VERSION ""

NS_ :

BS_:

BU_: Central_ECU Radar
VAL_TABLE_ Location_Validity 1 "Valid" 0 "Invalid" ;

BO_ 16 Ego_Vehicle_Movement: 16 Central_ECU
 SG_ Ego_Veh_CRC : 0|16@1+ (1,0) [0|65535] ""  Radar
 SG_ Ego_Veh_AliveCtr : 16|8@1+ (1,0) [0|255] ""  Radar
 SG_ Ego_Veh_YawRate : 56|16@1+ (0.0078125,-180) [-180|180] "deg/s"  Radar
 SG_ Ego_Veh_vx : 24|15@1+ (0.0039063,-25) [-25|100] "m/s"  Radar
 SG_ Ego_Veh_Ax : 40|16@1+ (0.0019531,-59) [-59|59] "m/s^2"  Radar

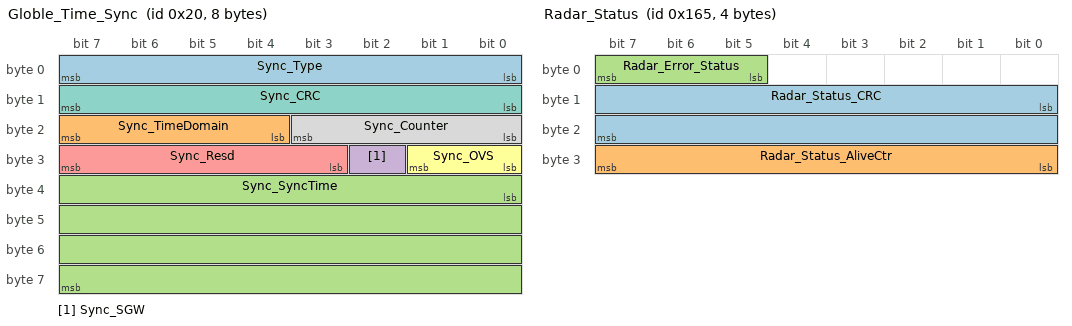
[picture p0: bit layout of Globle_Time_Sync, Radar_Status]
BO_ 32 Globle_Time_Sync: 8 Central_ECU
 SG_ Sync_Type : 0|8@1+ (1,0) [0|255] ""  Radar
 SG_ Sync_TimeDomain : 20|4@1+ (1,0) [0|15] ""  Radar
 SG_ Sync_SyncTime : 32|32@1+ (1,0) [0|4294967295] ""  Radar
 SG_ Sync_SGW : 26|1@1+ (1,0) [0|1] ""  Radar
 SG_ Sync_Resd : 27|5@1+ (1,0) [0|31] ""  Radar
 SG_ Sync_OVS : 24|2@1+ (1,0) [0|3] ""  Radar
 SG_ Sync_CRC : 8|8@1+ (1,0) [0|255] ""  Radar
 SG_ Sync_Counter : 16|4@1+ (1,0) [0|15] ""  Radar

BO_ 1969 Diag_Response: 64 Radar
 SG_ Diag_Response_Dummy : 0|64@1+ (1,0) [0|1.84467440737096E+019] ""  Central_ECU

BO_ 1841 Diag_Req_Physical: 64 Central_ECU
 SG_ Diag_Request_Phys_Dummy : 0|64@1+ (1,0) [0|1.84467440737096E+019] ""  Radar

BO_ 2015 Diag_Req_Functional: 64 Central_ECU
 SG_ Diag_Request_Func_Dummy : 0|64@1+ (1,0) [0|1.84467440737096E+019] ""  Radar

BO_ 357 Radar_Status: 4 Radar
 SG_ Radar_Status_CRC : 8|16@1+ (1,0) [0|65535] "" Vector__XXX
 SG_ Radar_Status_AliveCtr : 24|8@1+ (1,0) [0|255] "" Vector__XXX
 SG_ Radar_Error_Status : 5|3@1+ (1,0) [0|15] ""  Central_ECU

BO_ 256 Loc_List_Header: 12 Radar
 SG_ LocHeader_TimestampStatus : 54|8@1+ (1,0) [0|255] ""  Central_ECU
 SG_ LocHeader_Timestamp : 9|41@1+ (0.1,0) [0|219902325555.1] "ms"  Central_ECU
 SG_ LocHeader_Reserved : 62|10@1+ (1,0) [0|1023] ""  Central_ECU
 SG_ LocHeader_NumLoc : 0|9@1+ (1,0) [0|342] ""  Central_ECU
 SG_ LocHeader_CRC : 72|16@1+ (1,0) [0|65535] ""  Central_ECU
 SG_ LocHeader_Blockcnt : 50|4@1+ (1,0) [0|15] ""  Central_ECU
 SG_ LocHeader_AliveCtr : 88|8@1+ (1,0) [0|255] ""  Central_ECU

BO_ 356 Location_Data_64: 64 Radar
 SG_ Loc_ElevAngleQly_64_004 : 416|8@1+ (1,0) [0|255] ""  Central_ECU
 SG_ Loc_ElevAngleQly_64_003 : 392|8@1+ (1,0) [0|255] ""  Central_ECU
 SG_ Loc_ElevAngleQly_64_002 : 368|8@1+ (1,0) [0|255] ""  Central_ECU
 SG_ Loc_ElevAngleQly_64_001 : 344|8@1+ (1,0) [0|255] ""  Central_ECU
 SG_ Loc_AziAngleQly_64_004 : 408|8@1+ (1,0) [0|255] ""  Central_ECU
 SG_ Loc_AziAngleQly_64_003 : 384|8@1+ (1,0) [0|255] ""  Central_ECU
 SG_ Loc_AziAngleQly_64_002 : 360|8@1+ (1,0) [0|255] ""  Central_ECU
 SG_ Loc_AziAngleQly_64_001 : 336|8@1+ (1,0) [0|255] ""  Central_ECU
 SG_ Loc_RadialDistVeloQly_64_004 : 400|8@1+ (1,0) [0|255] ""  Central_ECU
 SG_ Loc_RadialDistVeloQly_64_003 : 376|8@1+ (1,0) [0|255] ""  Central_ECU
 SG_ Loc_RadialDistVeloQly_64_002 : 352|8@1+ (1,0) [0|255] ""  Central_ECU
 SG_ Loc_RadialDistVeloQly_64_001 : 328|8@1+ (1,0) [0|255] ""  Central_ECU
 SG_ Loc_Validity_64_004 : 327|1@1+ (1,0) [0|1] ""  Central_ECU
 SG_ Loc_Validity_64_003 : 326|1@1+ (1,0) [0|1] ""  Central_ECU
 SG_ Loc_Validity_64_002 : 325|1@1+ (1,0) [0|1] ""  Central_ECU
 SG_ Loc_Validity_64_001 : 324|1@1+ (1,0) [0|1] ""  Central_ECU
 SG_ Loc_64_Blockcnt : 320|4@1+ (1,0) [0|15] ""  Central_ECU
 SG_ Loc_64_CRC : 296|16@1+ (1,0) [0|65535] ""  Central_ECU
 SG_ Loc_64_AliveCtr : 312|8@1+ (1,0) [0|255] ""  Central_ECU
 SG_ Loc_SNR_64_004 : 237|11@1+ (0.0625,0) [0|40] "dB"  Central_ECU
 SG_ Loc_SNR_64_003 : 163|11@1+ (0.0625,0) [0|40] "dB"  Central_ECU
 SG_ Loc_SNR_64_002 : 89|11@1+ (0.0625,0) [0|40] "dB"  Central_ECU
 SG_ Loc_RCS_64_004 : 286|10@1+ (0.125,-50) [-50|70] "dBm^2"  Central_ECU
 SG_ Loc_RCS_64_003 : 212|10@1+ (0.125,-50) [-50|70] "dBm^2"  Central_ECU
 SG_ Loc_RCS_64_002 : 138|10@1+ (0.125,-50) [-50|70] "dBm^2"  Central_ECU
 SG_ Loc_RadialVelo_64_004 : 248|15@1+ (0.0078125,-128) [-128|127] "m/s"  Central_ECU
 SG_ Loc_RadialVelo_64_003 : 174|15@1+ (0.0078125,-128) [-128|127] "m/s"  Central_ECU
 SG_ Loc_RadialVelo_64_002 : 100|15@1+ (0.0078125,-128) [-128|127] "m/s"  Central_ECU
 SG_ Loc_RadialDist_64_004 : 222|15@1+ (0.0078125,0) [0|250] "m"  Central_ECU
 SG_ Loc_RadialDist_64_003 : 148|15@1+ (0.0078125,0) [0|250] "m"  Central_ECU
 SG_ Loc_RadialDist_64_002 : 74|15@1+ (0.0078125,0) [0|250] "m"  Central_ECU
 SG_ Loc_ElevAngle_64_004 : 275|11@1+ (0.001,-0.785) [-0.785|0.785] "rad"  Central_ECU
 SG_ Loc_ElevAngle_64_003 : 201|11@1+ (0.001,-0.785) [-0.785|0.785] "rad"  Central_ECU
 SG_ Loc_ElevAngle_64_002 : 127|11@1+ (0.001,-0.785) [-0.785|0.785] "rad"  Central_ECU
 SG_ Loc_AziAngle_64_004 : 263|12@1+ (0.001,-1.57) [-1.57|1.57] "rad"  Central_ECU
 SG_ Loc_AziAngle_64_003 : 189|12@1+ (0.001,-1.57) [-1.57|1.57] "rad"  Central_ECU
 SG_ Loc_AziAngle_64_002 : 115|12@1+ (0.001,-1.57) [-1.57|1.57] "rad"  Central_ECU
 SG_ Loc_RCS_64_001 : 64|10@1+ (0.125,-50) [-50|70] "dBm^2"  Central_ECU
 SG_ Loc_ElevAngle_64_001 : 53|11@1+ (0.001,-0.785) [-0.785|0.785] "rad"  Central_ECU
 SG_ Loc_AziAngle_64_001 : 41|12@1+ (0.001,-1.57) [-1.57|1.57] "rad"  Central_ECU
 SG_ Loc_RadialVelo_64_001 : 26|15@1+ (0.0078125,-128) [-128|127] "m/s"  Central_ECU
 SG_ Loc_SNR_64_001 : 15|11@1+ (0.0625,0) [0|40] "dB"  Central_ECU
 SG_ Loc_RadialDist_64_001 : 0|15@1+ (0.0078125,0) [0|250] "m"  Central_ECU

BO_ 355 Location_Data_63: 64 Radar
 SG_ Loc_ElevAngleQly_63_004 : 416|8@1+ (1,0) [0|255] ""  Central_ECU
 SG_ Loc_ElevAngleQly_63_003 : 392|8@1+ (1,0) [0|255] ""  Central_ECU
 SG_ Loc_ElevAngleQly_63_002 : 368|8@1+ (1,0) [0|255] ""  Central_ECU
 SG_ Loc_ElevAngleQly_63_001 : 344|8@1+ (1,0) [0|255] ""  Central_ECU
 SG_ Loc_AziAngleQly_63_004 : 408|8@1+ (1,0) [0|255] ""  Central_ECU
 SG_ Loc_AziAngleQly_63_003 : 384|8@1+ (1,0) [0|255] ""  Central_ECU
 SG_ Loc_AziAngleQly_63_002 : 360|8@1+ (1,0) [0|255] ""  Central_ECU
 SG_ Loc_AziAngleQly_63_001 : 336|8@1+ (1,0) [0|255] ""  Central_ECU
 SG_ Loc_RadialDistVeloQly_63_004 : 400|8@1+ (1,0) [0|255] ""  Central_ECU
 SG_ Loc_RadialDistVeloQly_63_003 : 376|8@1+ (1,0) [0|255] ""  Central_ECU
 SG_ Loc_RadialDistVeloQly_63_002 : 352|8@1+ (1,0) [0|255] ""  Central_ECU
 SG_ Loc_RadialDistVeloQly_63_001 : 328|8@1+ (1,0) [0|255] ""  Central_ECU
 SG_ Loc_Validity_63_004 : 327|1@1+ (1,0) [0|1] ""  Central_ECU
 SG_ Loc_Validity_63_003 : 326|1@1+ (1,0) [0|1] ""  Central_ECU
 SG_ Loc_Validity_63_002 : 325|1@1+ (1,0) [0|1] ""  Central_ECU
 SG_ Loc_Validity_63_001 : 324|1@1+ (1,0) [0|1] ""  Central_ECU
 SG_ Loc_63_Blockcnt : 320|4@1+ (1,0) [0|15] ""  Central_ECU
 SG_ Loc_63_CRC : 296|16@1+ (1,0) [0|65535] ""  Central_ECU
 SG_ Loc_63_AliveCtr : 312|8@1+ (1,0) [0|255] ""  Central_ECU
 SG_ Loc_SNR_63_004 : 237|11@1+ (0.0625,0) [0|40] "dB"  Central_ECU
 SG_ Loc_SNR_63_003 : 163|11@1+ (0.0625,0) [0|40] "dB"  Central_ECU
 SG_ Loc_SNR_63_002 : 89|11@1+ (0.0625,0) [0|40] "dB"  Central_ECU
 SG_ Loc_RCS_63_004 : 286|10@1+ (0.125,-50) [-50|70] "dBm^2"  Central_ECU
 SG_ Loc_RCS_63_003 : 212|10@1+ (0.125,-50) [-50|70] "dBm^2"  Central_ECU
 SG_ Loc_RCS_63_002 : 138|10@1+ (0.125,-50) [-50|70] "dBm^2"  Central_ECU
 SG_ Loc_RadialVelo_63_004 : 248|15@1+ (0.0078125,-128) [-128|127] "m/s"  Central_ECU
 SG_ Loc_RadialVelo_63_003 : 174|15@1+ (0.0078125,-128) [-128|127] "m/s"  Central_ECU
 SG_ Loc_RadialVelo_63_002 : 100|15@1+ (0.0078125,-128) [-128|127] "m/s"  Central_ECU
 SG_ Loc_RadialDist_63_004 : 222|15@1+ (0.0078125,0) [0|250] "m"  Central_ECU
 SG_ Loc_RadialDist_63_003 : 148|15@1+ (0.0078125,0) [0|250] "m"  Central_ECU
 SG_ Loc_RadialDist_63_002 : 74|15@1+ (0.0078125,0) [0|250] "m"  Central_ECU
 SG_ Loc_ElevAngle_63_004 : 275|11@1+ (0.001,-0.785) [-0.785|0.785] "rad"  Central_ECU
 SG_ Loc_ElevAngle_63_003 : 201|11@1+ (0.001,-0.785) [-0.785|0.785] "rad"  Central_ECU
 SG_ Loc_ElevAngle_63_002 : 127|11@1+ (0.001,-0.785) [-0.785|0.785] "rad"  Central_ECU
 SG_ Loc_AziAngle_63_004 : 263|12@1+ (0.001,-1.57) [-1.57|1.57] "rad"  Central_ECU
 SG_ Loc_AziAngle_63_003 : 189|12@1+ (0.001,-1.57) [-1.57|1.57] "rad"  Central_ECU
 SG_ Loc_AziAngle_63_002 : 115|12@1+ (0.001,-1.57) [-1.57|1.57] "rad"  Central_ECU
 SG_ Loc_RCS_63_001 : 64|10@1+ (0.125,-50) [-50|70] "dBm^2"  Central_ECU
 SG_ Loc_ElevAngle_63_001 : 53|11@1+ (0.001,-0.785) [-0.785|0.785] "rad"  Central_ECU
 SG_ Loc_AziAngle_63_001 : 41|12@1+ (0.001,-1.57) [-1.57|1.57] "rad"  Central_ECU
 SG_ Loc_RadialVelo_63_001 : 26|15@1+ (0.0078125,-128) [-128|127] "m/s"  Central_ECU
 SG_ Loc_SNR_63_001 : 15|11@1+ (0.0625,0) [0|40] "dB"  Central_ECU
 SG_ Loc_RadialDist_63_001 : 0|15@1+ (0.0078125,0) [0|250] "m"  Central_ECU

BO_ 354 Location_Data_62: 64 Radar
 SG_ Loc_ElevAngleQly_62_004 : 416|8@1+ (1,0) [0|255] ""  Central_ECU
 SG_ Loc_ElevAngleQly_62_003 : 392|8@1+ (1,0) [0|255] ""  Central_ECU
 SG_ Loc_ElevAngleQly_62_002 : 368|8@1+ (1,0) [0|255] ""  Central_ECU
 SG_ Loc_ElevAngleQly_62_001 : 344|8@1+ (1,0) [0|255] ""  Central_ECU
 SG_ Loc_AziAngleQly_62_004 : 408|8@1+ (1,0) [0|255] ""  Central_ECU
 SG_ Loc_AziAngleQly_62_003 : 384|8@1+ (1,0) [0|255] ""  Central_ECU
 SG_ Loc_AziAngleQly_62_002 : 360|8@1+ (1,0) [0|255] ""  Central_ECU
 SG_ Loc_AziAngleQly_62_001 : 336|8@1+ (1,0) [0|255] ""  Central_ECU
 SG_ Loc_RadialDistVeloQly_62_004 : 400|8@1+ (1,0) [0|255] ""  Central_ECU
 SG_ Loc_RadialDistVeloQly_62_003 : 376|8@1+ (1,0) [0|255] ""  Central_ECU
 SG_ Loc_RadialDistVeloQly_62_002 : 352|8@1+ (1,0) [0|255] ""  Central_ECU
 SG_ Loc_RadialDistVeloQly_62_001 : 328|8@1+ (1,0) [0|255] ""  Central_ECU
 SG_ Loc_Validity_62_004 : 327|1@1+ (1,0) [0|1] ""  Central_ECU
 SG_ Loc_Validity_62_003 : 326|1@1+ (1,0) [0|1] ""  Central_ECU
 SG_ Loc_Validity_62_002 : 325|1@1+ (1,0) [0|1] ""  Central_ECU
 SG_ Loc_Validity_62_001 : 324|1@1+ (1,0) [0|1] ""  Central_ECU
 SG_ Loc_62_Blockcnt : 320|4@1+ (1,0) [0|15] ""  Central_ECU
 SG_ Loc_62_CRC : 296|16@1+ (1,0) [0|65535] ""  Central_ECU
 SG_ Loc_62_AliveCtr : 312|8@1+ (1,0) [0|255] ""  Central_ECU
 SG_ Loc_SNR_62_004 : 237|11@1+ (0.0625,0) [0|40] "dB"  Central_ECU
 SG_ Loc_SNR_62_003 : 163|11@1+ (0.0625,0) [0|40] "dB"  Central_ECU
 SG_ Loc_SNR_62_002 : 89|11@1+ (0.0625,0) [0|40] "dB"  Central_ECU
 SG_ Loc_RCS_62_004 : 286|10@1+ (0.125,-50) [-50|70] "dBm^2"  Central_ECU
 SG_ Loc_RCS_62_003 : 212|10@1+ (0.125,-50) [-50|70] "dBm^2"  Central_ECU
 SG_ Loc_RCS_62_002 : 138|10@1+ (0.125,-50) [-50|70] "dBm^2"  Central_ECU
 SG_ Loc_RadialVelo_62_004 : 248|15@1+ (0.0078125,-128) [-128|127] "m/s"  Central_ECU
 SG_ Loc_RadialVelo_62_003 : 174|15@1+ (0.0078125,-128) [-128|127] "m/s"  Central_ECU
 SG_ Loc_RadialVelo_62_002 : 100|15@1+ (0.0078125,-128) [-128|127] "m/s"  Central_ECU
 SG_ Loc_RadialDist_62_004 : 222|15@1+ (0.0078125,0) [0|250] "m"  Central_ECU
 SG_ Loc_RadialDist_62_003 : 148|15@1+ (0.0078125,0) [0|250] "m"  Central_ECU
 SG_ Loc_RadialDist_62_002 : 74|15@1+ (0.0078125,0) [0|250] "m"  Central_ECU
 SG_ Loc_ElevAngle_62_004 : 275|11@1+ (0.001,-0.785) [-0.785|0.785] "rad"  Central_ECU
 SG_ Loc_ElevAngle_62_003 : 201|11@1+ (0.001,-0.785) [-0.785|0.785] "rad"  Central_ECU
 SG_ Loc_ElevAngle_62_002 : 127|11@1+ (0.001,-0.785) [-0.785|0.785] "rad"  Central_ECU
 SG_ Loc_AziAngle_62_004 : 263|12@1+ (0.001,-1.57) [-1.57|1.57] "rad"  Central_ECU
 SG_ Loc_AziAngle_62_003 : 189|12@1+ (0.001,-1.57) [-1.57|1.57] "rad"  Central_ECU
 SG_ Loc_AziAngle_62_002 : 115|12@1+ (0.001,-1.57) [-1.57|1.57] "rad"  Central_ECU
 SG_ Loc_RCS_62_001 : 64|10@1+ (0.125,-50) [-50|70] "dBm^2"  Central_ECU
 SG_ Loc_ElevAngle_62_001 : 53|11@1+ (0.001,-0.785) [-0.785|0.785] "rad"  Central_ECU
 SG_ Loc_AziAngle_62_001 : 41|12@1+ (0.001,-1.57) [-1.57|1.57] "rad"  Central_ECU
 SG_ Loc_RadialVelo_62_001 : 26|15@1+ (0.0078125,-128) [-128|127] "m/s"  Central_ECU
 SG_ Loc_SNR_62_001 : 15|11@1+ (0.0625,0) [0|40] "dB"  Central_ECU
 SG_ Loc_RadialDist_62_001 : 0|15@1+ (0.0078125,0) [0|250] "m"  Central_ECU

BO_ 353 Location_Data_61: 64 Radar
 SG_ Loc_ElevAngleQly_61_004 : 416|8@1+ (1,0) [0|255] ""  Central_ECU
 SG_ Loc_ElevAngleQly_61_003 : 392|8@1+ (1,0) [0|255] ""  Central_ECU
 SG_ Loc_ElevAngleQly_61_002 : 368|8@1+ (1,0) [0|255] ""  Central_ECU
 SG_ Loc_ElevAngleQly_61_001 : 344|8@1+ (1,0) [0|255] ""  Central_ECU
 SG_ Loc_AziAngleQly_61_004 : 408|8@1+ (1,0) [0|255] ""  Central_ECU
 SG_ Loc_AziAngleQly_61_003 : 384|8@1+ (1,0) [0|255] ""  Central_ECU
 SG_ Loc_AziAngleQly_61_002 : 360|8@1+ (1,0) [0|255] ""  Central_ECU
 SG_ Loc_AziAngleQly_61_001 : 336|8@1+ (1,0) [0|255] ""  Central_ECU
 SG_ Loc_RadialDistVeloQly_61_004 : 400|8@1+ (1,0) [0|255] ""  Central_ECU
 SG_ Loc_RadialDistVeloQly_61_003 : 376|8@1+ (1,0) [0|255] ""  Central_ECU
 SG_ Loc_RadialDistVeloQly_61_002 : 352|8@1+ (1,0) [0|255] ""  Central_ECU
 SG_ Loc_RadialDistVeloQly_61_001 : 328|8@1+ (1,0) [0|255] ""  Central_ECU
 SG_ Loc_Validity_61_004 : 327|1@1+ (1,0) [0|1] ""  Central_ECU
 SG_ Loc_Validity_61_003 : 326|1@1+ (1,0) [0|1] ""  Central_ECU
 SG_ Loc_Validity_61_002 : 325|1@1+ (1,0) [0|1] ""  Central_ECU
 SG_ Loc_Validity_61_001 : 324|1@1+ (1,0) [0|1] ""  Central_ECU
 SG_ Loc_61_Blockcnt : 320|4@1+ (1,0) [0|15] ""  Central_ECU
 SG_ Loc_61_CRC : 296|16@1+ (1,0) [0|65535] ""  Central_ECU
 SG_ Loc_61_AliveCtr : 312|8@1+ (1,0) [0|255] ""  Central_ECU
 SG_ Loc_SNR_61_004 : 237|11@1+ (0.0625,0) [0|40] "dB"  Central_ECU
 SG_ Loc_SNR_61_003 : 163|11@1+ (0.0625,0) [0|40] "dB"  Central_ECU
 SG_ Loc_SNR_61_002 : 89|11@1+ (0.0625,0) [0|40] "dB"  Central_ECU
 SG_ Loc_RCS_61_004 : 286|10@1+ (0.125,-50) [-50|70] "dBm^2"  Central_ECU
 SG_ Loc_RCS_61_003 : 212|10@1+ (0.125,-50) [-50|70] "dBm^2"  Central_ECU
 SG_ Loc_RCS_61_002 : 138|10@1+ (0.125,-50) [-50|70] "dBm^2"  Central_ECU
 SG_ Loc_RadialVelo_61_004 : 248|15@1+ (0.0078125,-128) [-128|127] "m/s"  Central_ECU
 SG_ Loc_RadialVelo_61_003 : 174|15@1+ (0.0078125,-128) [-128|127] "m/s"  Central_ECU
 SG_ Loc_RadialVelo_61_002 : 100|15@1+ (0.0078125,-128) [-128|127] "m/s"  Central_ECU
 SG_ Loc_RadialDist_61_004 : 222|15@1+ (0.0078125,0) [0|250] "m"  Central_ECU
 SG_ Loc_RadialDist_61_003 : 148|15@1+ (0.0078125,0) [0|250] "m"  Central_ECU
 SG_ Loc_RadialDist_61_002 : 74|15@1+ (0.0078125,0) [0|250] "m"  Central_ECU
 SG_ Loc_ElevAngle_61_004 : 275|11@1+ (0.001,-0.785) [-0.785|0.785] "rad"  Central_ECU
 SG_ Loc_ElevAngle_61_003 : 201|11@1+ (0.001,-0.785) [-0.785|0.785] "rad"  Central_ECU
 SG_ Loc_ElevAngle_61_002 : 127|11@1+ (0.001,-0.785) [-0.785|0.785] "rad"  Central_ECU
 SG_ Loc_AziAngle_61_004 : 263|12@1+ (0.001,-1.57) [-1.57|1.57] "rad"  Central_ECU
 SG_ Loc_AziAngle_61_003 : 189|12@1+ (0.001,-1.57) [-1.57|1.57] "rad"  Central_ECU
 SG_ Loc_AziAngle_61_002 : 115|12@1+ (0.001,-1.57) [-1.57|1.57] "rad"  Central_ECU
 SG_ Loc_RCS_61_001 : 64|10@1+ (0.125,-50) [-50|70] "dBm^2"  Central_ECU
 SG_ Loc_ElevAngle_61_001 : 53|11@1+ (0.001,-0.785) [-0.785|0.785] "rad"  Central_ECU
 SG_ Loc_AziAngle_61_001 : 41|12@1+ (0.001,-1.57) [-1.57|1.57] "rad"  Central_ECU
 SG_ Loc_RadialVelo_61_001 : 26|15@1+ (0.0078125,-128) [-128|127] "m/s"  Central_ECU
 SG_ Loc_SNR_61_001 : 15|11@1+ (0.0625,0) [0|40] "dB"  Central_ECU
 SG_ Loc_RadialDist_61_001 : 0|15@1+ (0.0078125,0) [0|250] "m"  Central_ECU

BO_ 352 Location_Data_60: 64 Radar
 SG_ Loc_ElevAngleQly_60_004 : 416|8@1+ (1,0) [0|255] ""  Central_ECU
 SG_ Loc_ElevAngleQly_60_003 : 392|8@1+ (1,0) [0|255] ""  Central_ECU
 SG_ Loc_ElevAngleQly_60_002 : 368|8@1+ (1,0) [0|255] ""  Central_ECU
 SG_ Loc_ElevAngleQly_60_001 : 344|8@1+ (1,0) [0|255] ""  Central_ECU
 SG_ Loc_AziAngleQly_60_004 : 408|8@1+ (1,0) [0|255] ""  Central_ECU
 SG_ Loc_AziAngleQly_60_003 : 384|8@1+ (1,0) [0|255] ""  Central_ECU
 SG_ Loc_AziAngleQly_60_002 : 360|8@1+ (1,0) [0|255] ""  Central_ECU
 SG_ Loc_AziAngleQly_60_001 : 336|8@1+ (1,0) [0|255] ""  Central_ECU
 SG_ Loc_RadialDistVeloQly_60_004 : 400|8@1+ (1,0) [0|255] ""  Central_ECU
 SG_ Loc_RadialDistVeloQly_60_003 : 376|8@1+ (1,0) [0|255] ""  Central_ECU
 SG_ Loc_RadialDistVeloQly_60_002 : 352|8@1+ (1,0) [0|255] ""  Central_ECU
 SG_ Loc_RadialDistVeloQly_60_001 : 328|8@1+ (1,0) [0|255] ""  Central_ECU
 SG_ Loc_Validity_60_004 : 327|1@1+ (1,0) [0|1] ""  Central_ECU
 SG_ Loc_Validity_60_003 : 326|1@1+ (1,0) [0|1] ""  Central_ECU
 SG_ Loc_Validity_60_002 : 325|1@1+ (1,0) [0|1] ""  Central_ECU
 SG_ Loc_Validity_60_001 : 324|1@1+ (1,0) [0|1] ""  Central_ECU
 SG_ Loc_60_Blockcnt : 320|4@1+ (1,0) [0|15] ""  Central_ECU
 SG_ Loc_60_CRC : 296|16@1+ (1,0) [0|65535] ""  Central_ECU
 SG_ Loc_60_AliveCtr : 312|8@1+ (1,0) [0|255] ""  Central_ECU
 SG_ Loc_SNR_60_004 : 237|11@1+ (0.0625,0) [0|40] "dB"  Central_ECU
 SG_ Loc_SNR_60_003 : 163|11@1+ (0.0625,0) [0|40] "dB"  Central_ECU
 SG_ Loc_SNR_60_002 : 89|11@1+ (0.0625,0) [0|40] "dB"  Central_ECU
 SG_ Loc_RCS_60_004 : 286|10@1+ (0.125,-50) [-50|70] "dBm^2"  Central_ECU
 SG_ Loc_RCS_60_003 : 212|10@1+ (0.125,-50) [-50|70] "dBm^2"  Central_ECU
 SG_ Loc_RCS_60_002 : 138|10@1+ (0.125,-50) [-50|70] "dBm^2"  Central_ECU
 SG_ Loc_RadialVelo_60_004 : 248|15@1+ (0.0078125,-128) [-128|127] "m/s"  Central_ECU
 SG_ Loc_RadialVelo_60_003 : 174|15@1+ (0.0078125,-128) [-128|127] "m/s"  Central_ECU
 SG_ Loc_RadialVelo_60_002 : 100|15@1+ (0.0078125,-128) [-128|127] "m/s"  Central_ECU
 SG_ Loc_RadialDist_60_004 : 222|15@1+ (0.0078125,0) [0|250] "m"  Central_ECU
 SG_ Loc_RadialDist_60_003 : 148|15@1+ (0.0078125,0) [0|250] "m"  Central_ECU
 SG_ Loc_RadialDist_60_002 : 74|15@1+ (0.0078125,0) [0|250] "m"  Central_ECU
 SG_ Loc_ElevAngle_60_004 : 275|11@1+ (0.001,-0.785) [-0.785|0.785] "rad"  Central_ECU
 SG_ Loc_ElevAngle_60_003 : 201|11@1+ (0.001,-0.785) [-0.785|0.785] "rad"  Central_ECU
 SG_ Loc_ElevAngle_60_002 : 127|11@1+ (0.001,-0.785) [-0.785|0.785] "rad"  Central_ECU
 SG_ Loc_AziAngle_60_004 : 263|12@1+ (0.001,-1.57) [-1.57|1.57] "rad"  Central_ECU
 SG_ Loc_AziAngle_60_003 : 189|12@1+ (0.001,-1.57) [-1.57|1.57] "rad"  Central_ECU
 SG_ Loc_AziAngle_60_002 : 115|12@1+ (0.001,-1.57) [-1.57|1.57] "rad"  Central_ECU
 SG_ Loc_RCS_60_001 : 64|10@1+ (0.125,-50) [-50|70] "dBm^2"  Central_ECU
 SG_ Loc_ElevAngle_60_001 : 53|11@1+ (0.001,-0.785) [-0.785|0.785] "rad"  Central_ECU
 SG_ Loc_AziAngle_60_001 : 41|12@1+ (0.001,-1.57) [-1.57|1.57] "rad"  Central_ECU
 SG_ Loc_RadialVelo_60_001 : 26|15@1+ (0.0078125,-128) [-128|127] "m/s"  Central_ECU
 SG_ Loc_SNR_60_001 : 15|11@1+ (0.0625,0) [0|40] "dB"  Central_ECU
 SG_ Loc_RadialDist_60_001 : 0|15@1+ (0.0078125,0) [0|250] "m"  Central_ECU

BO_ 345 Location_Data_59: 64 Radar
 SG_ Loc_ElevAngleQly_59_004 : 416|8@1+ (1,0) [0|255] ""  Central_ECU
 SG_ Loc_ElevAngleQly_59_003 : 392|8@1+ (1,0) [0|255] ""  Central_ECU
 SG_ Loc_ElevAngleQly_59_002 : 368|8@1+ (1,0) [0|255] ""  Central_ECU
 SG_ Loc_ElevAngleQly_59_001 : 344|8@1+ (1,0) [0|255] ""  Central_ECU
 SG_ Loc_AziAngleQly_59_004 : 408|8@1+ (1,0) [0|255] ""  Central_ECU
 SG_ Loc_AziAngleQly_59_003 : 384|8@1+ (1,0) [0|255] ""  Central_ECU
 SG_ Loc_AziAngleQly_59_002 : 360|8@1+ (1,0) [0|255] ""  Central_ECU
 SG_ Loc_AziAngleQly_59_001 : 336|8@1+ (1,0) [0|255] ""  Central_ECU
 SG_ Loc_RadialDistVeloQly_59_004 : 400|8@1+ (1,0) [0|255] ""  Central_ECU
 SG_ Loc_RadialDistVeloQly_59_003 : 376|8@1+ (1,0) [0|255] ""  Central_ECU
 SG_ Loc_RadialDistVeloQly_59_002 : 352|8@1+ (1,0) [0|255] ""  Central_ECU
 SG_ Loc_RadialDistVeloQly_59_001 : 328|8@1+ (1,0) [0|255] ""  Central_ECU
 SG_ Loc_Validity_59_004 : 327|1@1+ (1,0) [0|1] ""  Central_ECU
 SG_ Loc_Validity_59_003 : 326|1@1+ (1,0) [0|1] ""  Central_ECU
 SG_ Loc_Validity_59_002 : 325|1@1+ (1,0) [0|1] ""  Central_ECU
 SG_ Loc_Validity_59_001 : 324|1@1+ (1,0) [0|1] ""  Central_ECU
 SG_ Loc_59_Blockcnt : 320|4@1+ (1,0) [0|15] ""  Central_ECU
 SG_ Loc_59_CRC : 296|16@1+ (1,0) [0|65535] ""  Central_ECU
 SG_ Loc_59_AliveCtr : 312|8@1+ (1,0) [0|255] ""  Central_ECU
 SG_ Loc_SNR_59_004 : 237|11@1+ (0.0625,0) [0|40] "dB"  Central_ECU
 SG_ Loc_SNR_59_003 : 163|11@1+ (0.0625,0) [0|40] "dB"  Central_ECU
 SG_ Loc_SNR_59_002 : 89|11@1+ (0.0625,0) [0|40] "dB"  Central_ECU
 SG_ Loc_RCS_59_004 : 286|10@1+ (0.125,-50) [-50|70] "dBm^2"  Central_ECU
 SG_ Loc_RCS_59_003 : 212|10@1+ (0.125,-50) [-50|70] "dBm^2"  Central_ECU
 SG_ Loc_RCS_59_002 : 138|10@1+ (0.125,-50) [-50|70] "dBm^2"  Central_ECU
 SG_ Loc_RadialVelo_59_004 : 248|15@1+ (0.0078125,-128) [-128|127] "m/s"  Central_ECU
 SG_ Loc_RadialVelo_59_003 : 174|15@1+ (0.0078125,-128) [-128|127] "m/s"  Central_ECU
 SG_ Loc_RadialVelo_59_002 : 100|15@1+ (0.0078125,-128) [-128|127] "m/s"  Central_ECU
 SG_ Loc_RadialDist_59_004 : 222|15@1+ (0.0078125,0) [0|250] "m"  Central_ECU
 SG_ Loc_RadialDist_59_003 : 148|15@1+ (0.0078125,0) [0|250] "m"  Central_ECU
 SG_ Loc_RadialDist_59_002 : 74|15@1+ (0.0078125,0) [0|250] "m"  Central_ECU
 SG_ Loc_ElevAngle_59_004 : 275|11@1+ (0.001,-0.785) [-0.785|0.785] "rad"  Central_ECU
 SG_ Loc_ElevAngle_59_003 : 201|11@1+ (0.001,-0.785) [-0.785|0.785] "rad"  Central_ECU
 SG_ Loc_ElevAngle_59_002 : 127|11@1+ (0.001,-0.785) [-0.785|0.785] "rad"  Central_ECU
 SG_ Loc_AziAngle_59_004 : 263|12@1+ (0.001,-1.57) [-1.57|1.57] "rad"  Central_ECU
 SG_ Loc_AziAngle_59_003 : 189|12@1+ (0.001,-1.57) [-1.57|1.57] "rad"  Central_ECU
 SG_ Loc_AziAngle_59_002 : 115|12@1+ (0.001,-1.57) [-1.57|1.57] "rad"  Central_ECU
 SG_ Loc_RCS_59_001 : 64|10@1+ (0.125,-50) [-50|70] "dBm^2"  Central_ECU
 SG_ Loc_ElevAngle_59_001 : 53|11@1+ (0.001,-0.785) [-0.785|0.785] "rad"  Central_ECU
 SG_ Loc_AziAngle_59_001 : 41|12@1+ (0.001,-1.57) [-1.57|1.57] "rad"  Central_ECU
 SG_ Loc_RadialVelo_59_001 : 26|15@1+ (0.0078125,-128) [-128|127] "m/s"  Central_ECU
 SG_ Loc_SNR_59_001 : 15|11@1+ (0.0625,0) [0|40] "dB"  Central_ECU
 SG_ Loc_RadialDist_59_001 : 0|15@1+ (0.0078125,0) [0|250] "m"  Central_ECU

BO_ 344 Location_Data_58: 64 Radar
 SG_ Loc_ElevAngleQly_58_004 : 416|8@1+ (1,0) [0|255] ""  Central_ECU
 SG_ Loc_ElevAngleQly_58_003 : 392|8@1+ (1,0) [0|255] ""  Central_ECU
 SG_ Loc_ElevAngleQly_58_002 : 368|8@1+ (1,0) [0|255] ""  Central_ECU
 SG_ Loc_ElevAngleQly_58_001 : 344|8@1+ (1,0) [0|255] ""  Central_ECU
 SG_ Loc_AziAngleQly_58_004 : 408|8@1+ (1,0) [0|255] ""  Central_ECU
 SG_ Loc_AziAngleQly_58_003 : 384|8@1+ (1,0) [0|255] ""  Central_ECU
 SG_ Loc_AziAngleQly_58_002 : 360|8@1+ (1,0) [0|255] ""  Central_ECU
 SG_ Loc_AziAngleQly_58_001 : 336|8@1+ (1,0) [0|255] ""  Central_ECU
 SG_ Loc_RadialDistVeloQly_58_004 : 400|8@1+ (1,0) [0|255] ""  Central_ECU
 SG_ Loc_RadialDistVeloQly_58_003 : 376|8@1+ (1,0) [0|255] ""  Central_ECU
 SG_ Loc_RadialDistVeloQly_58_002 : 352|8@1+ (1,0) [0|255] ""  Central_ECU
 SG_ Loc_RadialDistVeloQly_58_001 : 328|8@1+ (1,0) [0|255] ""  Central_ECU
 SG_ Loc_Validity_58_004 : 327|1@1+ (1,0) [0|1] ""  Central_ECU
 SG_ Loc_Validity_58_003 : 326|1@1+ (1,0) [0|1] ""  Central_ECU
 SG_ Loc_Validity_58_002 : 325|1@1+ (1,0) [0|1] ""  Central_ECU
 SG_ Loc_Validity_58_001 : 324|1@1+ (1,0) [0|1] ""  Central_ECU
 SG_ Loc_58_Blockcnt : 320|4@1+ (1,0) [0|15] ""  Central_ECU
 SG_ Loc_58_CRC : 296|16@1+ (1,0) [0|65535] ""  Central_ECU
 SG_ Loc_58_AliveCtr : 312|8@1+ (1,0) [0|255] ""  Central_ECU
 SG_ Loc_SNR_58_004 : 237|11@1+ (0.0625,0) [0|40] "dB"  Central_ECU
 SG_ Loc_SNR_58_003 : 163|11@1+ (0.0625,0) [0|40] "dB"  Central_ECU
 SG_ Loc_SNR_58_002 : 89|11@1+ (0.0625,0) [0|40] "dB"  Central_ECU
 SG_ Loc_RCS_58_004 : 286|10@1+ (0.125,-50) [-50|70] "dBm^2"  Central_ECU
 SG_ Loc_RCS_58_003 : 212|10@1+ (0.125,-50) [-50|70] "dBm^2"  Central_ECU
 SG_ Loc_RCS_58_002 : 138|10@1+ (0.125,-50) [-50|70] "dBm^2"  Central_ECU
 SG_ Loc_RadialVelo_58_004 : 248|15@1+ (0.0078125,-128) [-128|127] "m/s"  Central_ECU
 SG_ Loc_RadialVelo_58_003 : 174|15@1+ (0.0078125,-128) [-128|127] "m/s"  Central_ECU
 SG_ Loc_RadialVelo_58_002 : 100|15@1+ (0.0078125,-128) [-128|127] "m/s"  Central_ECU
 SG_ Loc_RadialDist_58_004 : 222|15@1+ (0.0078125,0) [0|250] "m"  Central_ECU
 SG_ Loc_RadialDist_58_003 : 148|15@1+ (0.0078125,0) [0|250] "m"  Central_ECU
 SG_ Loc_RadialDist_58_002 : 74|15@1+ (0.0078125,0) [0|250] "m"  Central_ECU
 SG_ Loc_ElevAngle_58_004 : 275|11@1+ (0.001,-0.785) [-0.785|0.785] "rad"  Central_ECU
 SG_ Loc_ElevAngle_58_003 : 201|11@1+ (0.001,-0.785) [-0.785|0.785] "rad"  Central_ECU
 SG_ Loc_ElevAngle_58_002 : 127|11@1+ (0.001,-0.785) [-0.785|0.785] "rad"  Central_ECU
 SG_ Loc_AziAngle_58_004 : 263|12@1+ (0.001,-1.57) [-1.57|1.57] "rad"  Central_ECU
 SG_ Loc_AziAngle_58_003 : 189|12@1+ (0.001,-1.57) [-1.57|1.57] "rad"  Central_ECU
 SG_ Loc_AziAngle_58_002 : 115|12@1+ (0.001,-1.57) [-1.57|1.57] "rad"  Central_ECU
 SG_ Loc_RCS_58_001 : 64|10@1+ (0.125,-50) [-50|70] "dBm^2"  Central_ECU
 SG_ Loc_ElevAngle_58_001 : 53|11@1+ (0.001,-0.785) [-0.785|0.785] "rad"  Central_ECU
 SG_ Loc_AziAngle_58_001 : 41|12@1+ (0.001,-1.57) [-1.57|1.57] "rad"  Central_ECU
 SG_ Loc_RadialVelo_58_001 : 26|15@1+ (0.0078125,-128) [-128|127] "m/s"  Central_ECU
 SG_ Loc_SNR_58_001 : 15|11@1+ (0.0625,0) [0|40] "dB"  Central_ECU
 SG_ Loc_RadialDist_58_001 : 0|15@1+ (0.0078125,0) [0|250] "m"  Central_ECU

BO_ 343 Location_Data_57: 64 Radar
 SG_ Loc_ElevAngleQly_57_004 : 416|8@1+ (1,0) [0|255] ""  Central_ECU
 SG_ Loc_ElevAngleQly_57_003 : 392|8@1+ (1,0) [0|255] ""  Central_ECU
 SG_ Loc_ElevAngleQly_57_002 : 368|8@1+ (1,0) [0|255] ""  Central_ECU
 SG_ Loc_ElevAngleQly_57_001 : 344|8@1+ (1,0) [0|255] ""  Central_ECU
 SG_ Loc_AziAngleQly_57_004 : 408|8@1+ (1,0) [0|255] ""  Central_ECU
 SG_ Loc_AziAngleQly_57_003 : 384|8@1+ (1,0) [0|255] ""  Central_ECU
 SG_ Loc_AziAngleQly_57_002 : 360|8@1+ (1,0) [0|255] ""  Central_ECU
 SG_ Loc_AziAngleQly_57_001 : 336|8@1+ (1,0) [0|255] ""  Central_ECU
 SG_ Loc_RadialDistVeloQly_57_004 : 400|8@1+ (1,0) [0|255] ""  Central_ECU
 SG_ Loc_RadialDistVeloQly_57_003 : 376|8@1+ (1,0) [0|255] ""  Central_ECU
 SG_ Loc_RadialDistVeloQly_57_002 : 352|8@1+ (1,0) [0|255] ""  Central_ECU
 SG_ Loc_RadialDistVeloQly_57_001 : 328|8@1+ (1,0) [0|255] ""  Central_ECU
 SG_ Loc_Validity_57_004 : 327|1@1+ (1,0) [0|1] ""  Central_ECU
 SG_ Loc_Validity_57_003 : 326|1@1+ (1,0) [0|1] ""  Central_ECU
 SG_ Loc_Validity_57_002 : 325|1@1+ (1,0) [0|1] ""  Central_ECU
 SG_ Loc_Validity_57_001 : 324|1@1+ (1,0) [0|1] ""  Central_ECU
 SG_ Loc_57_Blockcnt : 320|4@1+ (1,0) [0|15] ""  Central_ECU
 SG_ Loc_57_CRC : 296|16@1+ (1,0) [0|65535] ""  Central_ECU
 SG_ Loc_57_AliveCtr : 312|8@1+ (1,0) [0|255] ""  Central_ECU
 SG_ Loc_SNR_57_004 : 237|11@1+ (0.0625,0) [0|40] "dB"  Central_ECU
 SG_ Loc_SNR_57_003 : 163|11@1+ (0.0625,0) [0|40] "dB"  Central_ECU
 SG_ Loc_SNR_57_002 : 89|11@1+ (0.0625,0) [0|40] "dB"  Central_ECU
 SG_ Loc_RCS_57_004 : 286|10@1+ (0.125,-50) [-50|70] "dBm^2"  Central_ECU
 SG_ Loc_RCS_57_003 : 212|10@1+ (0.125,-50) [-50|70] "dBm^2"  Central_ECU
 SG_ Loc_RCS_57_002 : 138|10@1+ (0.125,-50) [-50|70] "dBm^2"  Central_ECU
 SG_ Loc_RadialVelo_57_004 : 248|15@1+ (0.0078125,-128) [-128|127] "m/s"  Central_ECU
 SG_ Loc_RadialVelo_57_003 : 174|15@1+ (0.0078125,-128) [-128|127] "m/s"  Central_ECU
 SG_ Loc_RadialVelo_57_002 : 100|15@1+ (0.0078125,-128) [-128|127] "m/s"  Central_ECU
 SG_ Loc_RadialDist_57_004 : 222|15@1+ (0.0078125,0) [0|250] "m"  Central_ECU
 SG_ Loc_RadialDist_57_003 : 148|15@1+ (0.0078125,0) [0|250] "m"  Central_ECU
 SG_ Loc_RadialDist_57_002 : 74|15@1+ (0.0078125,0) [0|250] "m"  Central_ECU
 SG_ Loc_ElevAngle_57_004 : 275|11@1+ (0.001,-0.785) [-0.785|0.785] "rad"  Central_ECU
 SG_ Loc_ElevAngle_57_003 : 201|11@1+ (0.001,-0.785) [-0.785|0.785] "rad"  Central_ECU
 SG_ Loc_ElevAngle_57_002 : 127|11@1+ (0.001,-0.785) [-0.785|0.785] "rad"  Central_ECU
 SG_ Loc_AziAngle_57_004 : 263|12@1+ (0.001,-1.57) [-1.57|1.57] "rad"  Central_ECU
 SG_ Loc_AziAngle_57_003 : 189|12@1+ (0.001,-1.57) [-1.57|1.57] "rad"  Central_ECU
 SG_ Loc_AziAngle_57_002 : 115|12@1+ (0.001,-1.57) [-1.57|1.57] "rad"  Central_ECU
 SG_ Loc_RCS_57_001 : 64|10@1+ (0.125,-50) [-50|70] "dBm^2"  Central_ECU
 SG_ Loc_ElevAngle_57_001 : 53|11@1+ (0.001,-0.785) [-0.785|0.785] "rad"  Central_ECU
 SG_ Loc_AziAngle_57_001 : 41|12@1+ (0.001,-1.57) [-1.57|1.57] "rad"  Central_ECU
 SG_ Loc_RadialVelo_57_001 : 26|15@1+ (0.0078125,-128) [-128|127] "m/s"  Central_ECU
 SG_ Loc_SNR_57_001 : 15|11@1+ (0.0625,0) [0|40] "dB"  Central_ECU
 SG_ Loc_RadialDist_57_001 : 0|15@1+ (0.0078125,0) [0|250] "m"  Central_ECU

BO_ 342 Location_Data_56: 64 Radar
 SG_ Loc_ElevAngleQly_56_004 : 416|8@1+ (1,0) [0|255] ""  Central_ECU
 SG_ Loc_ElevAngleQly_56_003 : 392|8@1+ (1,0) [0|255] ""  Central_ECU
 SG_ Loc_ElevAngleQly_56_002 : 368|8@1+ (1,0) [0|255] ""  Central_ECU
 SG_ Loc_ElevAngleQly_56_001 : 344|8@1+ (1,0) [0|255] ""  Central_ECU
 SG_ Loc_AziAngleQly_56_004 : 408|8@1+ (1,0) [0|255] ""  Central_ECU
 SG_ Loc_AziAngleQly_56_003 : 384|8@1+ (1,0) [0|255] ""  Central_ECU
 SG_ Loc_AziAngleQly_56_002 : 360|8@1+ (1,0) [0|255] ""  Central_ECU
 SG_ Loc_AziAngleQly_56_001 : 336|8@1+ (1,0) [0|255] ""  Central_ECU
 SG_ Loc_RadialDistVeloQly_56_004 : 400|8@1+ (1,0) [0|255] ""  Central_ECU
 SG_ Loc_RadialDistVeloQly_56_003 : 376|8@1+ (1,0) [0|255] ""  Central_ECU
 SG_ Loc_RadialDistVeloQly_56_002 : 352|8@1+ (1,0) [0|255] ""  Central_ECU
 SG_ Loc_RadialDistVeloQly_56_001 : 328|8@1+ (1,0) [0|255] ""  Central_ECU
 SG_ Loc_Validity_56_004 : 327|1@1+ (1,0) [0|1] ""  Central_ECU
 SG_ Loc_Validity_56_003 : 326|1@1+ (1,0) [0|1] ""  Central_ECU
 SG_ Loc_Validity_56_002 : 325|1@1+ (1,0) [0|1] ""  Central_ECU
 SG_ Loc_Validity_56_001 : 324|1@1+ (1,0) [0|1] ""  Central_ECU
 SG_ Loc_56_Blockcnt : 320|4@1+ (1,0) [0|15] ""  Central_ECU
 SG_ Loc_56_CRC : 296|16@1+ (1,0) [0|65535] ""  Central_ECU
 SG_ Loc_56_AliveCtr : 312|8@1+ (1,0) [0|255] ""  Central_ECU
 SG_ Loc_SNR_56_004 : 237|11@1+ (0.0625,0) [0|40] "dB"  Central_ECU
 SG_ Loc_SNR_56_003 : 163|11@1+ (0.0625,0) [0|40] "dB"  Central_ECU
 SG_ Loc_SNR_56_002 : 89|11@1+ (0.0625,0) [0|40] "dB"  Central_ECU
 SG_ Loc_RCS_56_004 : 286|10@1+ (0.125,-50) [-50|70] "dBm^2"  Central_ECU
 SG_ Loc_RCS_56_003 : 212|10@1+ (0.125,-50) [-50|70] "dBm^2"  Central_ECU
 SG_ Loc_RCS_56_002 : 138|10@1+ (0.125,-50) [-50|70] "dBm^2"  Central_ECU
 SG_ Loc_RadialVelo_56_004 : 248|15@1+ (0.0078125,-128) [-128|127] "m/s"  Central_ECU
 SG_ Loc_RadialVelo_56_003 : 174|15@1+ (0.0078125,-128) [-128|127] "m/s"  Central_ECU
 SG_ Loc_RadialVelo_56_002 : 100|15@1+ (0.0078125,-128) [-128|127] "m/s"  Central_ECU
 SG_ Loc_RadialDist_56_004 : 222|15@1+ (0.0078125,0) [0|250] "m"  Central_ECU
 SG_ Loc_RadialDist_56_003 : 148|15@1+ (0.0078125,0) [0|250] "m"  Central_ECU
 SG_ Loc_RadialDist_56_002 : 74|15@1+ (0.0078125,0) [0|250] "m"  Central_ECU
 SG_ Loc_ElevAngle_56_004 : 275|11@1+ (0.001,-0.785) [-0.785|0.785] "rad"  Central_ECU
 SG_ Loc_ElevAngle_56_003 : 201|11@1+ (0.001,-0.785) [-0.785|0.785] "rad"  Central_ECU
 SG_ Loc_ElevAngle_56_002 : 127|11@1+ (0.001,-0.785) [-0.785|0.785] "rad"  Central_ECU
 SG_ Loc_AziAngle_56_004 : 263|12@1+ (0.001,-1.57) [-1.57|1.57] "rad"  Central_ECU
 SG_ Loc_AziAngle_56_003 : 189|12@1+ (0.001,-1.57) [-1.57|1.57] "rad"  Central_ECU
 SG_ Loc_AziAngle_56_002 : 115|12@1+ (0.001,-1.57) [-1.57|1.57] "rad"  Central_ECU
 SG_ Loc_RCS_56_001 : 64|10@1+ (0.125,-50) [-50|70] "dBm^2"  Central_ECU
 SG_ Loc_ElevAngle_56_001 : 53|11@1+ (0.001,-0.785) [-0.785|0.785] "rad"  Central_ECU
 SG_ Loc_AziAngle_56_001 : 41|12@1+ (0.001,-1.57) [-1.57|1.57] "rad"  Central_ECU
 SG_ Loc_RadialVelo_56_001 : 26|15@1+ (0.0078125,-128) [-128|127] "m/s"  Central_ECU
 SG_ Loc_SNR_56_001 : 15|11@1+ (0.0625,0) [0|40] "dB"  Central_ECU
 SG_ Loc_RadialDist_56_001 : 0|15@1+ (0.0078125,0) [0|250] "m"  Central_ECU

BO_ 341 Location_Data_55: 64 Radar
 SG_ Loc_ElevAngleQly_55_004 : 416|8@1+ (1,0) [0|255] ""  Central_ECU
 SG_ Loc_ElevAngleQly_55_003 : 392|8@1+ (1,0) [0|255] ""  Central_ECU
 SG_ Loc_ElevAngleQly_55_002 : 368|8@1+ (1,0) [0|255] ""  Central_ECU
 SG_ Loc_ElevAngleQly_55_001 : 344|8@1+ (1,0) [0|255] ""  Central_ECU
 SG_ Loc_AziAngleQly_55_004 : 408|8@1+ (1,0) [0|255] ""  Central_ECU
 SG_ Loc_AziAngleQly_55_003 : 384|8@1+ (1,0) [0|255] ""  Central_ECU
 SG_ Loc_AziAngleQly_55_002 : 360|8@1+ (1,0) [0|255] ""  Central_ECU
 SG_ Loc_AziAngleQly_55_001 : 336|8@1+ (1,0) [0|255] ""  Central_ECU
 SG_ Loc_RadialDistVeloQly_55_004 : 400|8@1+ (1,0) [0|255] ""  Central_ECU
 SG_ Loc_RadialDistVeloQly_55_003 : 376|8@1+ (1,0) [0|255] ""  Central_ECU
 SG_ Loc_RadialDistVeloQly_55_002 : 352|8@1+ (1,0) [0|255] ""  Central_ECU
 SG_ Loc_RadialDistVeloQly_55_001 : 328|8@1+ (1,0) [0|255] ""  Central_ECU
 SG_ Loc_Validity_55_004 : 327|1@1+ (1,0) [0|1] ""  Central_ECU
 SG_ Loc_Validity_55_003 : 326|1@1+ (1,0) [0|1] ""  Central_ECU
 SG_ Loc_Validity_55_002 : 325|1@1+ (1,0) [0|1] ""  Central_ECU
 SG_ Loc_Validity_55_001 : 324|1@1+ (1,0) [0|1] ""  Central_ECU
 SG_ Loc_55_Blockcnt : 320|4@1+ (1,0) [0|15] ""  Central_ECU
 SG_ Loc_55_CRC : 296|16@1+ (1,0) [0|65535] ""  Central_ECU
 SG_ Loc_55_AliveCtr : 312|8@1+ (1,0) [0|255] ""  Central_ECU
 SG_ Loc_SNR_55_004 : 237|11@1+ (0.0625,0) [0|40] "dB"  Central_ECU
 SG_ Loc_SNR_55_003 : 163|11@1+ (0.0625,0) [0|40] "dB"  Central_ECU
 SG_ Loc_SNR_55_002 : 89|11@1+ (0.0625,0) [0|40] "dB"  Central_ECU
 SG_ Loc_RCS_55_004 : 286|10@1+ (0.125,-50) [-50|70] "dBm^2"  Central_ECU
 SG_ Loc_RCS_55_003 : 212|10@1+ (0.125,-50) [-50|70] "dBm^2"  Central_ECU
 SG_ Loc_RCS_55_002 : 138|10@1+ (0.125,-50) [-50|70] "dBm^2"  Central_ECU
 SG_ Loc_RadialVelo_55_004 : 248|15@1+ (0.0078125,-128) [-128|127] "m/s"  Central_ECU
 SG_ Loc_RadialVelo_55_003 : 174|15@1+ (0.0078125,-128) [-128|127] "m/s"  Central_ECU
 SG_ Loc_RadialVelo_55_002 : 100|15@1+ (0.0078125,-128) [-128|127] "m/s"  Central_ECU
 SG_ Loc_RadialDist_55_004 : 222|15@1+ (0.0078125,0) [0|250] "m"  Central_ECU
 SG_ Loc_RadialDist_55_003 : 148|15@1+ (0.0078125,0) [0|250] "m"  Central_ECU
 SG_ Loc_RadialDist_55_002 : 74|15@1+ (0.0078125,0) [0|250] "m"  Central_ECU
 SG_ Loc_ElevAngle_55_004 : 275|11@1+ (0.001,-0.785) [-0.785|0.785] "rad"  Central_ECU
 SG_ Loc_ElevAngle_55_003 : 201|11@1+ (0.001,-0.785) [-0.785|0.785] "rad"  Central_ECU
 SG_ Loc_ElevAngle_55_002 : 127|11@1+ (0.001,-0.785) [-0.785|0.785] "rad"  Central_ECU
 SG_ Loc_AziAngle_55_004 : 263|12@1+ (0.001,-1.57) [-1.57|1.57] "rad"  Central_ECU
 SG_ Loc_AziAngle_55_003 : 189|12@1+ (0.001,-1.57) [-1.57|1.57] "rad"  Central_ECU
 SG_ Loc_AziAngle_55_002 : 115|12@1+ (0.001,-1.57) [-1.57|1.57] "rad"  Central_ECU
 SG_ Loc_RCS_55_001 : 64|10@1+ (0.125,-50) [-50|70] "dBm^2"  Central_ECU
 SG_ Loc_ElevAngle_55_001 : 53|11@1+ (0.001,-0.785) [-0.785|0.785] "rad"  Central_ECU
 SG_ Loc_AziAngle_55_001 : 41|12@1+ (0.001,-1.57) [-1.57|1.57] "rad"  Central_ECU
 SG_ Loc_RadialVelo_55_001 : 26|15@1+ (0.0078125,-128) [-128|127] "m/s"  Central_ECU
 SG_ Loc_SNR_55_001 : 15|11@1+ (0.0625,0) [0|40] "dB"  Central_ECU
 SG_ Loc_RadialDist_55_001 : 0|15@1+ (0.0078125,0) [0|250] "m"  Central_ECU

BO_ 340 Location_Data_54: 64 Radar
 SG_ Loc_ElevAngleQly_54_004 : 416|8@1+ (1,0) [0|255] ""  Central_ECU
 SG_ Loc_ElevAngleQly_54_003 : 392|8@1+ (1,0) [0|255] ""  Central_ECU
 SG_ Loc_ElevAngleQly_54_002 : 368|8@1+ (1,0) [0|255] ""  Central_ECU
 SG_ Loc_ElevAngleQly_54_001 : 344|8@1+ (1,0) [0|255] ""  Central_ECU
 SG_ Loc_AziAngleQly_54_004 : 408|8@1+ (1,0) [0|255] ""  Central_ECU
 SG_ Loc_AziAngleQly_54_003 : 384|8@1+ (1,0) [0|255] ""  Central_ECU
 SG_ Loc_AziAngleQly_54_002 : 360|8@1+ (1,0) [0|255] ""  Central_ECU
 SG_ Loc_AziAngleQly_54_001 : 336|8@1+ (1,0) [0|255] ""  Central_ECU
 SG_ Loc_RadialDistVeloQly_54_004 : 400|8@1+ (1,0) [0|255] ""  Central_ECU
 SG_ Loc_RadialDistVeloQly_54_003 : 376|8@1+ (1,0) [0|255] ""  Central_ECU
 SG_ Loc_RadialDistVeloQly_54_002 : 352|8@1+ (1,0) [0|255] ""  Central_ECU
 SG_ Loc_RadialDistVeloQly_54_001 : 328|8@1+ (1,0) [0|255] ""  Central_ECU
 SG_ Loc_Validity_54_004 : 327|1@1+ (1,0) [0|1] ""  Central_ECU
 SG_ Loc_Validity_54_003 : 326|1@1+ (1,0) [0|1] ""  Central_ECU
 SG_ Loc_Validity_54_002 : 325|1@1+ (1,0) [0|1] ""  Central_ECU
 SG_ Loc_Validity_54_001 : 324|1@1+ (1,0) [0|1] ""  Central_ECU
 SG_ Loc_54_Blockcnt : 320|4@1+ (1,0) [0|15] ""  Central_ECU
 SG_ Loc_54_CRC : 296|16@1+ (1,0) [0|65535] ""  Central_ECU
 SG_ Loc_54_AliveCtr : 312|8@1+ (1,0) [0|255] ""  Central_ECU
 SG_ Loc_SNR_54_004 : 237|11@1+ (0.0625,0) [0|40] "dB"  Central_ECU
 SG_ Loc_SNR_54_003 : 163|11@1+ (0.0625,0) [0|40] "dB"  Central_ECU
 SG_ Loc_SNR_54_002 : 89|11@1+ (0.0625,0) [0|40] "dB"  Central_ECU
 SG_ Loc_RCS_54_004 : 286|10@1+ (0.125,-50) [-50|70] "dBm^2"  Central_ECU
 SG_ Loc_RCS_54_003 : 212|10@1+ (0.125,-50) [-50|70] "dBm^2"  Central_ECU
 SG_ Loc_RCS_54_002 : 138|10@1+ (0.125,-50) [-50|70] "dBm^2"  Central_ECU
 SG_ Loc_RadialVelo_54_004 : 248|15@1+ (0.0078125,-128) [-128|127] "m/s"  Central_ECU
 SG_ Loc_RadialVelo_54_003 : 174|15@1+ (0.0078125,-128) [-128|127] "m/s"  Central_ECU
 SG_ Loc_RadialVelo_54_002 : 100|15@1+ (0.0078125,-128) [-128|127] "m/s"  Central_ECU
 SG_ Loc_RadialDist_54_004 : 222|15@1+ (0.0078125,0) [0|250] "m"  Central_ECU
 SG_ Loc_RadialDist_54_003 : 148|15@1+ (0.0078125,0) [0|250] "m"  Central_ECU
 SG_ Loc_RadialDist_54_002 : 74|15@1+ (0.0078125,0) [0|250] "m"  Central_ECU
 SG_ Loc_ElevAngle_54_004 : 275|11@1+ (0.001,-0.785) [-0.785|0.785] "rad"  Central_ECU
 SG_ Loc_ElevAngle_54_003 : 201|11@1+ (0.001,-0.785) [-0.785|0.785] "rad"  Central_ECU
 SG_ Loc_ElevAngle_54_002 : 127|11@1+ (0.001,-0.785) [-0.785|0.785] "rad"  Central_ECU
 SG_ Loc_AziAngle_54_004 : 263|12@1+ (0.001,-1.57) [-1.57|1.57] "rad"  Central_ECU
 SG_ Loc_AziAngle_54_003 : 189|12@1+ (0.001,-1.57) [-1.57|1.57] "rad"  Central_ECU
 SG_ Loc_AziAngle_54_002 : 115|12@1+ (0.001,-1.57) [-1.57|1.57] "rad"  Central_ECU
 SG_ Loc_RCS_54_001 : 64|10@1+ (0.125,-50) [-50|70] "dBm^2"  Central_ECU
 SG_ Loc_ElevAngle_54_001 : 53|11@1+ (0.001,-0.785) [-0.785|0.785] "rad"  Central_ECU
 SG_ Loc_AziAngle_54_001 : 41|12@1+ (0.001,-1.57) [-1.57|1.57] "rad"  Central_ECU
 SG_ Loc_RadialVelo_54_001 : 26|15@1+ (0.0078125,-128) [-128|127] "m/s"  Central_ECU
 SG_ Loc_SNR_54_001 : 15|11@1+ (0.0625,0) [0|40] "dB"  Central_ECU
 SG_ Loc_RadialDist_54_001 : 0|15@1+ (0.0078125,0) [0|250] "m"  Central_ECU

BO_ 339 Location_Data_53: 64 Radar
 SG_ Loc_ElevAngleQly_53_004 : 416|8@1+ (1,0) [0|255] ""  Central_ECU
 SG_ Loc_ElevAngleQly_53_003 : 392|8@1+ (1,0) [0|255] ""  Central_ECU
 SG_ Loc_ElevAngleQly_53_002 : 368|8@1+ (1,0) [0|255] ""  Central_ECU
 SG_ Loc_ElevAngleQly_53_001 : 344|8@1+ (1,0) [0|255] ""  Central_ECU
 SG_ Loc_AziAngleQly_53_004 : 408|8@1+ (1,0) [0|255] ""  Central_ECU
 SG_ Loc_AziAngleQly_53_003 : 384|8@1+ (1,0) [0|255] ""  Central_ECU
 SG_ Loc_AziAngleQly_53_002 : 360|8@1+ (1,0) [0|255] ""  Central_ECU
 SG_ Loc_AziAngleQly_53_001 : 336|8@1+ (1,0) [0|255] ""  Central_ECU
 SG_ Loc_RadialDistVeloQly_53_004 : 400|8@1+ (1,0) [0|255] ""  Central_ECU
 SG_ Loc_RadialDistVeloQly_53_003 : 376|8@1+ (1,0) [0|255] ""  Central_ECU
 SG_ Loc_RadialDistVeloQly_53_002 : 352|8@1+ (1,0) [0|255] ""  Central_ECU
 SG_ Loc_RadialDistVeloQly_53_001 : 328|8@1+ (1,0) [0|255] ""  Central_ECU
 SG_ Loc_Validity_53_004 : 327|1@1+ (1,0) [0|1] ""  Central_ECU
 SG_ Loc_Validity_53_003 : 326|1@1+ (1,0) [0|1] ""  Central_ECU
 SG_ Loc_Validity_53_002 : 325|1@1+ (1,0) [0|1] ""  Central_ECU
 SG_ Loc_Validity_53_001 : 324|1@1+ (1,0) [0|1] ""  Central_ECU
 SG_ Loc_53_Blockcnt : 320|4@1+ (1,0) [0|15] ""  Central_ECU
 SG_ Loc_53_CRC : 296|16@1+ (1,0) [0|65535] ""  Central_ECU
 SG_ Loc_53_AliveCtr : 312|8@1+ (1,0) [0|255] ""  Central_ECU
 SG_ Loc_SNR_53_004 : 237|11@1+ (0.0625,0) [0|40] "dB"  Central_ECU
 SG_ Loc_SNR_53_003 : 163|11@1+ (0.0625,0) [0|40] "dB"  Central_ECU
 SG_ Loc_SNR_53_002 : 89|11@1+ (0.0625,0) [0|40] "dB"  Central_ECU
 SG_ Loc_RCS_53_004 : 286|10@1+ (0.125,-50) [-50|70] "dBm^2"  Central_ECU
 SG_ Loc_RCS_53_003 : 212|10@1+ (0.125,-50) [-50|70] "dBm^2"  Central_ECU
 SG_ Loc_RCS_53_002 : 138|10@1+ (0.125,-50) [-50|70] "dBm^2"  Central_ECU
 SG_ Loc_RadialVelo_53_004 : 248|15@1+ (0.0078125,-128) [-128|127] "m/s"  Central_ECU
 SG_ Loc_RadialVelo_53_003 : 174|15@1+ (0.0078125,-128) [-128|127] "m/s"  Central_ECU
 SG_ Loc_RadialVelo_53_002 : 100|15@1+ (0.0078125,-128) [-128|127] "m/s"  Central_ECU
 SG_ Loc_RadialDist_53_004 : 222|15@1+ (0.0078125,0) [0|250] "m"  Central_ECU
 SG_ Loc_RadialDist_53_003 : 148|15@1+ (0.0078125,0) [0|250] "m"  Central_ECU
 SG_ Loc_RadialDist_53_002 : 74|15@1+ (0.0078125,0) [0|250] "m"  Central_ECU
 SG_ Loc_ElevAngle_53_004 : 275|11@1+ (0.001,-0.785) [-0.785|0.785] "rad"  Central_ECU
 SG_ Loc_ElevAngle_53_003 : 201|11@1+ (0.001,-0.785) [-0.785|0.785] "rad"  Central_ECU
 SG_ Loc_ElevAngle_53_002 : 127|11@1+ (0.001,-0.785) [-0.785|0.785] "rad"  Central_ECU
 SG_ Loc_AziAngle_53_004 : 263|12@1+ (0.001,-1.57) [-1.57|1.57] "rad"  Central_ECU
 SG_ Loc_AziAngle_53_003 : 189|12@1+ (0.001,-1.57) [-1.57|1.57] "rad"  Central_ECU
 SG_ Loc_AziAngle_53_002 : 115|12@1+ (0.001,-1.57) [-1.57|1.57] "rad"  Central_ECU
 SG_ Loc_RCS_53_001 : 64|10@1+ (0.125,-50) [-50|70] "dBm^2"  Central_ECU
 SG_ Loc_ElevAngle_53_001 : 53|11@1+ (0.001,-0.785) [-0.785|0.785] "rad"  Central_ECU
 SG_ Loc_AziAngle_53_001 : 41|12@1+ (0.001,-1.57) [-1.57|1.57] "rad"  Central_ECU
 SG_ Loc_RadialVelo_53_001 : 26|15@1+ (0.0078125,-128) [-128|127] "m/s"  Central_ECU
 SG_ Loc_SNR_53_001 : 15|11@1+ (0.0625,0) [0|40] "dB"  Central_ECU
 SG_ Loc_RadialDist_53_001 : 0|15@1+ (0.0078125,0) [0|250] "m"  Central_ECU

BO_ 338 Location_Data_52: 64 Radar
 SG_ Loc_ElevAngleQly_52_004 : 416|8@1+ (1,0) [0|255] ""  Central_ECU
 SG_ Loc_ElevAngleQly_52_003 : 392|8@1+ (1,0) [0|255] ""  Central_ECU
 SG_ Loc_ElevAngleQly_52_002 : 368|8@1+ (1,0) [0|255] ""  Central_ECU
 SG_ Loc_ElevAngleQly_52_001 : 344|8@1+ (1,0) [0|255] ""  Central_ECU
 SG_ Loc_AziAngleQly_52_004 : 408|8@1+ (1,0) [0|255] ""  Central_ECU
 SG_ Loc_AziAngleQly_52_003 : 384|8@1+ (1,0) [0|255] ""  Central_ECU
 SG_ Loc_AziAngleQly_52_002 : 360|8@1+ (1,0) [0|255] ""  Central_ECU
 SG_ Loc_AziAngleQly_52_001 : 336|8@1+ (1,0) [0|255] ""  Central_ECU
 SG_ Loc_RadialDistVeloQly_52_004 : 400|8@1+ (1,0) [0|255] ""  Central_ECU
 SG_ Loc_RadialDistVeloQly_52_003 : 376|8@1+ (1,0) [0|255] ""  Central_ECU
 SG_ Loc_RadialDistVeloQly_52_002 : 352|8@1+ (1,0) [0|255] ""  Central_ECU
 SG_ Loc_RadialDistVeloQly_52_001 : 328|8@1+ (1,0) [0|255] ""  Central_ECU
 SG_ Loc_Validity_52_004 : 327|1@1+ (1,0) [0|1] ""  Central_ECU
 SG_ Loc_Validity_52_003 : 326|1@1+ (1,0) [0|1] ""  Central_ECU
 SG_ Loc_Validity_52_002 : 325|1@1+ (1,0) [0|1] ""  Central_ECU
 SG_ Loc_Validity_52_001 : 324|1@1+ (1,0) [0|1] ""  Central_ECU
 SG_ Loc_52_Blockcnt : 320|4@1+ (1,0) [0|15] ""  Central_ECU
 SG_ Loc_52_CRC : 296|16@1+ (1,0) [0|65535] ""  Central_ECU
 SG_ Loc_52_AliveCtr : 312|8@1+ (1,0) [0|255] ""  Central_ECU
 SG_ Loc_SNR_52_004 : 237|11@1+ (0.0625,0) [0|40] "dB"  Central_ECU
 SG_ Loc_SNR_52_003 : 163|11@1+ (0.0625,0) [0|40] "dB"  Central_ECU
 SG_ Loc_SNR_52_002 : 89|11@1+ (0.0625,0) [0|40] "dB"  Central_ECU
 SG_ Loc_RCS_52_004 : 286|10@1+ (0.125,-50) [-50|70] "dBm^2"  Central_ECU
 SG_ Loc_RCS_52_003 : 212|10@1+ (0.125,-50) [-50|70] "dBm^2"  Central_ECU
 SG_ Loc_RCS_52_002 : 138|10@1+ (0.125,-50) [-50|70] "dBm^2"  Central_ECU
 SG_ Loc_RadialVelo_52_004 : 248|15@1+ (0.0078125,-128) [-128|127] "m/s"  Central_ECU
 SG_ Loc_RadialVelo_52_003 : 174|15@1+ (0.0078125,-128) [-128|127] "m/s"  Central_ECU
 SG_ Loc_RadialVelo_52_002 : 100|15@1+ (0.0078125,-128) [-128|127] "m/s"  Central_ECU
 SG_ Loc_RadialDist_52_004 : 222|15@1+ (0.0078125,0) [0|250] "m"  Central_ECU
 SG_ Loc_RadialDist_52_003 : 148|15@1+ (0.0078125,0) [0|250] "m"  Central_ECU
 SG_ Loc_RadialDist_52_002 : 74|15@1+ (0.0078125,0) [0|250] "m"  Central_ECU
 SG_ Loc_ElevAngle_52_004 : 275|11@1+ (0.001,-0.785) [-0.785|0.785] "rad"  Central_ECU
 SG_ Loc_ElevAngle_52_003 : 201|11@1+ (0.001,-0.785) [-0.785|0.785] "rad"  Central_ECU
 SG_ Loc_ElevAngle_52_002 : 127|11@1+ (0.001,-0.785) [-0.785|0.785] "rad"  Central_ECU
 SG_ Loc_AziAngle_52_004 : 263|12@1+ (0.001,-1.57) [-1.57|1.57] "rad"  Central_ECU
 SG_ Loc_AziAngle_52_003 : 189|12@1+ (0.001,-1.57) [-1.57|1.57] "rad"  Central_ECU
 SG_ Loc_AziAngle_52_002 : 115|12@1+ (0.001,-1.57) [-1.57|1.57] "rad"  Central_ECU
 SG_ Loc_RCS_52_001 : 64|10@1+ (0.125,-50) [-50|70] "dBm^2"  Central_ECU
 SG_ Loc_ElevAngle_52_001 : 53|11@1+ (0.001,-0.785) [-0.785|0.785] "rad"  Central_ECU
 SG_ Loc_AziAngle_52_001 : 41|12@1+ (0.001,-1.57) [-1.57|1.57] "rad"  Central_ECU
 SG_ Loc_RadialVelo_52_001 : 26|15@1+ (0.0078125,-128) [-128|127] "m/s"  Central_ECU
 SG_ Loc_SNR_52_001 : 15|11@1+ (0.0625,0) [0|40] "dB"  Central_ECU
 SG_ Loc_RadialDist_52_001 : 0|15@1+ (0.0078125,0) [0|250] "m"  Central_ECU

BO_ 337 Location_Data_51: 64 Radar
 SG_ Loc_ElevAngleQly_51_004 : 416|8@1+ (1,0) [0|255] ""  Central_ECU
 SG_ Loc_ElevAngleQly_51_003 : 392|8@1+ (1,0) [0|255] ""  Central_ECU
 SG_ Loc_ElevAngleQly_51_002 : 368|8@1+ (1,0) [0|255] ""  Central_ECU
 SG_ Loc_ElevAngleQly_51_001 : 344|8@1+ (1,0) [0|255] ""  Central_ECU
 SG_ Loc_AziAngleQly_51_004 : 408|8@1+ (1,0) [0|255] ""  Central_ECU
 SG_ Loc_AziAngleQly_51_003 : 384|8@1+ (1,0) [0|255] ""  Central_ECU
 SG_ Loc_AziAngleQly_51_002 : 360|8@1+ (1,0) [0|255] ""  Central_ECU
 SG_ Loc_AziAngleQly_51_001 : 336|8@1+ (1,0) [0|255] ""  Central_ECU
 SG_ Loc_RadialDistVeloQly_51_004 : 400|8@1+ (1,0) [0|255] ""  Central_ECU
 SG_ Loc_RadialDistVeloQly_51_003 : 376|8@1+ (1,0) [0|255] ""  Central_ECU
 SG_ Loc_RadialDistVeloQly_51_002 : 352|8@1+ (1,0) [0|255] ""  Central_ECU
 SG_ Loc_RadialDistVeloQly_51_001 : 328|8@1+ (1,0) [0|255] ""  Central_ECU
 SG_ Loc_Validity_51_004 : 327|1@1+ (1,0) [0|1] ""  Central_ECU
 SG_ Loc_Validity_51_003 : 326|1@1+ (1,0) [0|1] ""  Central_ECU
 SG_ Loc_Validity_51_002 : 325|1@1+ (1,0) [0|1] ""  Central_ECU
 SG_ Loc_Validity_51_001 : 324|1@1+ (1,0) [0|1] ""  Central_ECU
 SG_ Loc_51_Blockcnt : 320|4@1+ (1,0) [0|15] ""  Central_ECU
 SG_ Loc_51_CRC : 296|16@1+ (1,0) [0|65535] ""  Central_ECU
 SG_ Loc_51_AliveCtr : 312|8@1+ (1,0) [0|255] ""  Central_ECU
 SG_ Loc_SNR_51_004 : 237|11@1+ (0.0625,0) [0|40] "dB"  Central_ECU
 SG_ Loc_SNR_51_003 : 163|11@1+ (0.0625,0) [0|40] "dB"  Central_ECU
 SG_ Loc_SNR_51_002 : 89|11@1+ (0.0625,0) [0|40] "dB"  Central_ECU
 SG_ Loc_RCS_51_004 : 286|10@1+ (0.125,-50) [-50|70] "dBm^2"  Central_ECU
 SG_ Loc_RCS_51_003 : 212|10@1+ (0.125,-50) [-50|70] "dBm^2"  Central_ECU
 SG_ Loc_RCS_51_002 : 138|10@1+ (0.125,-50) [-50|70] "dBm^2"  Central_ECU
 SG_ Loc_RadialVelo_51_004 : 248|15@1+ (0.0078125,-128) [-128|127] "m/s"  Central_ECU
 SG_ Loc_RadialVelo_51_003 : 174|15@1+ (0.0078125,-128) [-128|127] "m/s"  Central_ECU
 SG_ Loc_RadialVelo_51_002 : 100|15@1+ (0.0078125,-128) [-128|127] "m/s"  Central_ECU
 SG_ Loc_RadialDist_51_004 : 222|15@1+ (0.0078125,0) [0|250] "m"  Central_ECU
 SG_ Loc_RadialDist_51_003 : 148|15@1+ (0.0078125,0) [0|250] "m"  Central_ECU
 SG_ Loc_RadialDist_51_002 : 74|15@1+ (0.0078125,0) [0|250] "m"  Central_ECU
 SG_ Loc_ElevAngle_51_004 : 275|11@1+ (0.001,-0.785) [-0.785|0.785] "rad"  Central_ECU
 SG_ Loc_ElevAngle_51_003 : 201|11@1+ (0.001,-0.785) [-0.785|0.785] "rad"  Central_ECU
 SG_ Loc_ElevAngle_51_002 : 127|11@1+ (0.001,-0.785) [-0.785|0.785] "rad"  Central_ECU
 SG_ Loc_AziAngle_51_004 : 263|12@1+ (0.001,-1.57) [-1.57|1.57] "rad"  Central_ECU
 SG_ Loc_AziAngle_51_003 : 189|12@1+ (0.001,-1.57) [-1.57|1.57] "rad"  Central_ECU
 SG_ Loc_AziAngle_51_002 : 115|12@1+ (0.001,-1.57) [-1.57|1.57] "rad"  Central_ECU
 SG_ Loc_RCS_51_001 : 64|10@1+ (0.125,-50) [-50|70] "dBm^2"  Central_ECU
 SG_ Loc_ElevAngle_51_001 : 53|11@1+ (0.001,-0.785) [-0.785|0.785] "rad"  Central_ECU
 SG_ Loc_AziAngle_51_001 : 41|12@1+ (0.001,-1.57) [-1.57|1.57] "rad"  Central_ECU
 SG_ Loc_RadialVelo_51_001 : 26|15@1+ (0.0078125,-128) [-128|127] "m/s"  Central_ECU
 SG_ Loc_SNR_51_001 : 15|11@1+ (0.0625,0) [0|40] "dB"  Central_ECU
 SG_ Loc_RadialDist_51_001 : 0|15@1+ (0.0078125,0) [0|250] "m"  Central_ECU

BO_ 336 Location_Data_50: 64 Radar
 SG_ Loc_ElevAngleQly_50_004 : 416|8@1+ (1,0) [0|255] ""  Central_ECU
 SG_ Loc_ElevAngleQly_50_003 : 392|8@1+ (1,0) [0|255] ""  Central_ECU
 SG_ Loc_ElevAngleQly_50_002 : 368|8@1+ (1,0) [0|255] ""  Central_ECU
 SG_ Loc_ElevAngleQly_50_001 : 344|8@1+ (1,0) [0|255] ""  Central_ECU
 SG_ Loc_AziAngleQly_50_004 : 408|8@1+ (1,0) [0|255] ""  Central_ECU
 SG_ Loc_AziAngleQly_50_003 : 384|8@1+ (1,0) [0|255] ""  Central_ECU
 SG_ Loc_AziAngleQly_50_002 : 360|8@1+ (1,0) [0|255] ""  Central_ECU
 SG_ Loc_AziAngleQly_50_001 : 336|8@1+ (1,0) [0|255] ""  Central_ECU
 SG_ Loc_RadialDistVeloQly_50_004 : 400|8@1+ (1,0) [0|255] ""  Central_ECU
 SG_ Loc_RadialDistVeloQly_50_003 : 376|8@1+ (1,0) [0|255] ""  Central_ECU
 SG_ Loc_RadialDistVeloQly_50_002 : 352|8@1+ (1,0) [0|255] ""  Central_ECU
 SG_ Loc_RadialDistVeloQly_50_001 : 328|8@1+ (1,0) [0|255] ""  Central_ECU
 SG_ Loc_Validity_50_004 : 327|1@1+ (1,0) [0|1] ""  Central_ECU
 SG_ Loc_Validity_50_003 : 326|1@1+ (1,0) [0|1] ""  Central_ECU
 SG_ Loc_Validity_50_002 : 325|1@1+ (1,0) [0|1] ""  Central_ECU
 SG_ Loc_Validity_50_001 : 324|1@1+ (1,0) [0|1] ""  Central_ECU
 SG_ Loc_50_Blockcnt : 320|4@1+ (1,0) [0|15] ""  Central_ECU
 SG_ Loc_50_CRC : 296|16@1+ (1,0) [0|65535] ""  Central_ECU
 SG_ Loc_50_AliveCtr : 312|8@1+ (1,0) [0|255] ""  Central_ECU
 SG_ Loc_SNR_50_004 : 237|11@1+ (0.0625,0) [0|40] "dB"  Central_ECU
 SG_ Loc_SNR_50_003 : 163|11@1+ (0.0625,0) [0|40] "dB"  Central_ECU
 SG_ Loc_SNR_50_002 : 89|11@1+ (0.0625,0) [0|40] "dB"  Central_ECU
 SG_ Loc_RCS_50_004 : 286|10@1+ (0.125,-50) [-50|70] "dBm^2"  Central_ECU
 SG_ Loc_RCS_50_003 : 212|10@1+ (0.125,-50) [-50|70] "dBm^2"  Central_ECU
 SG_ Loc_RCS_50_002 : 138|10@1+ (0.125,-50) [-50|70] "dBm^2"  Central_ECU
 SG_ Loc_RadialVelo_50_004 : 248|15@1+ (0.0078125,-128) [-128|127] "m/s"  Central_ECU
 SG_ Loc_RadialVelo_50_003 : 174|15@1+ (0.0078125,-128) [-128|127] "m/s"  Central_ECU
 SG_ Loc_RadialVelo_50_002 : 100|15@1+ (0.0078125,-128) [-128|127] "m/s"  Central_ECU
 SG_ Loc_RadialDist_50_004 : 222|15@1+ (0.0078125,0) [0|250] "m"  Central_ECU
 SG_ Loc_RadialDist_50_003 : 148|15@1+ (0.0078125,0) [0|250] "m"  Central_ECU
 SG_ Loc_RadialDist_50_002 : 74|15@1+ (0.0078125,0) [0|250] "m"  Central_ECU
 SG_ Loc_ElevAngle_50_004 : 275|11@1+ (0.001,-0.785) [-0.785|0.785] "rad"  Central_ECU
 SG_ Loc_ElevAngle_50_003 : 201|11@1+ (0.001,-0.785) [-0.785|0.785] "rad"  Central_ECU
 SG_ Loc_ElevAngle_50_002 : 127|11@1+ (0.001,-0.785) [-0.785|0.785] "rad"  Central_ECU
 SG_ Loc_AziAngle_50_004 : 263|12@1+ (0.001,-1.57) [-1.57|1.57] "rad"  Central_ECU
 SG_ Loc_AziAngle_50_003 : 189|12@1+ (0.001,-1.57) [-1.57|1.57] "rad"  Central_ECU
 SG_ Loc_AziAngle_50_002 : 115|12@1+ (0.001,-1.57) [-1.57|1.57] "rad"  Central_ECU
 SG_ Loc_RCS_50_001 : 64|10@1+ (0.125,-50) [-50|70] "dBm^2"  Central_ECU
 SG_ Loc_ElevAngle_50_001 : 53|11@1+ (0.001,-0.785) [-0.785|0.785] "rad"  Central_ECU
 SG_ Loc_AziAngle_50_001 : 41|12@1+ (0.001,-1.57) [-1.57|1.57] "rad"  Central_ECU
 SG_ Loc_RadialVelo_50_001 : 26|15@1+ (0.0078125,-128) [-128|127] "m/s"  Central_ECU
 SG_ Loc_SNR_50_001 : 15|11@1+ (0.0625,0) [0|40] "dB"  Central_ECU
 SG_ Loc_RadialDist_50_001 : 0|15@1+ (0.0078125,0) [0|250] "m"  Central_ECU

BO_ 329 Location_Data_49: 64 Radar
 SG_ Loc_ElevAngleQly_49_004 : 416|8@1+ (1,0) [0|255] ""  Central_ECU
 SG_ Loc_ElevAngleQly_49_003 : 392|8@1+ (1,0) [0|255] ""  Central_ECU
 SG_ Loc_ElevAngleQly_49_002 : 368|8@1+ (1,0) [0|255] ""  Central_ECU
 SG_ Loc_ElevAngleQly_49_001 : 344|8@1+ (1,0) [0|255] ""  Central_ECU
 SG_ Loc_AziAngleQly_49_004 : 408|8@1+ (1,0) [0|255] ""  Central_ECU
 SG_ Loc_AziAngleQly_49_003 : 384|8@1+ (1,0) [0|255] ""  Central_ECU
 SG_ Loc_AziAngleQly_49_002 : 360|8@1+ (1,0) [0|255] ""  Central_ECU
 SG_ Loc_AziAngleQly_49_001 : 336|8@1+ (1,0) [0|255] ""  Central_ECU
 SG_ Loc_RadialDistVeloQly_49_004 : 400|8@1+ (1,0) [0|255] ""  Central_ECU
 SG_ Loc_RadialDistVeloQly_49_003 : 376|8@1+ (1,0) [0|255] ""  Central_ECU
 SG_ Loc_RadialDistVeloQly_49_002 : 352|8@1+ (1,0) [0|255] ""  Central_ECU
 SG_ Loc_RadialDistVeloQly_49_001 : 328|8@1+ (1,0) [0|255] ""  Central_ECU
 SG_ Loc_Validity_49_004 : 327|1@1+ (1,0) [0|1] ""  Central_ECU
 SG_ Loc_Validity_49_003 : 326|1@1+ (1,0) [0|1] ""  Central_ECU
 SG_ Loc_Validity_49_002 : 325|1@1+ (1,0) [0|1] ""  Central_ECU
 SG_ Loc_Validity_49_001 : 324|1@1+ (1,0) [0|1] ""  Central_ECU
 SG_ Loc_49_Blockcnt : 320|4@1+ (1,0) [0|15] ""  Central_ECU
 SG_ Loc_49_CRC : 296|16@1+ (1,0) [0|65535] ""  Central_ECU
 SG_ Loc_49_AliveCtr : 312|8@1+ (1,0) [0|255] ""  Central_ECU
 SG_ Loc_SNR_49_004 : 237|11@1+ (0.0625,0) [0|40] "dB"  Central_ECU
 SG_ Loc_SNR_49_003 : 163|11@1+ (0.0625,0) [0|40] "dB"  Central_ECU
 SG_ Loc_SNR_49_002 : 89|11@1+ (0.0625,0) [0|40] "dB"  Central_ECU
 SG_ Loc_RCS_49_004 : 286|10@1+ (0.125,-50) [-50|70] "dBm^2"  Central_ECU
 SG_ Loc_RCS_49_003 : 212|10@1+ (0.125,-50) [-50|70] "dBm^2"  Central_ECU
 SG_ Loc_RCS_49_002 : 138|10@1+ (0.125,-50) [-50|70] "dBm^2"  Central_ECU
 SG_ Loc_RadialVelo_49_004 : 248|15@1+ (0.0078125,-128) [-128|127] "m/s"  Central_ECU
 SG_ Loc_RadialVelo_49_003 : 174|15@1+ (0.0078125,-128) [-128|127] "m/s"  Central_ECU
 SG_ Loc_RadialVelo_49_002 : 100|15@1+ (0.0078125,-128) [-128|127] "m/s"  Central_ECU
 SG_ Loc_RadialDist_49_004 : 222|15@1+ (0.0078125,0) [0|250] "m"  Central_ECU
 SG_ Loc_RadialDist_49_003 : 148|15@1+ (0.0078125,0) [0|250] "m"  Central_ECU
 SG_ Loc_RadialDist_49_002 : 74|15@1+ (0.0078125,0) [0|250] "m"  Central_ECU
 SG_ Loc_ElevAngle_49_004 : 275|11@1+ (0.001,-0.785) [-0.785|0.785] "rad"  Central_ECU
 SG_ Loc_ElevAngle_49_003 : 201|11@1+ (0.001,-0.785) [-0.785|0.785] "rad"  Central_ECU
 SG_ Loc_ElevAngle_49_002 : 127|11@1+ (0.001,-0.785) [-0.785|0.785] "rad"  Central_ECU
 SG_ Loc_AziAngle_49_004 : 263|12@1+ (0.001,-1.57) [-1.57|1.57] "rad"  Central_ECU
 SG_ Loc_AziAngle_49_003 : 189|12@1+ (0.001,-1.57) [-1.57|1.57] "rad"  Central_ECU
 SG_ Loc_AziAngle_49_002 : 115|12@1+ (0.001,-1.57) [-1.57|1.57] "rad"  Central_ECU
 SG_ Loc_RCS_49_001 : 64|10@1+ (0.125,-50) [-50|70] "dBm^2"  Central_ECU
 SG_ Loc_ElevAngle_49_001 : 53|11@1+ (0.001,-0.785) [-0.785|0.785] "rad"  Central_ECU
 SG_ Loc_AziAngle_49_001 : 41|12@1+ (0.001,-1.57) [-1.57|1.57] "rad"  Central_ECU
 SG_ Loc_RadialVelo_49_001 : 26|15@1+ (0.0078125,-128) [-128|127] "m/s"  Central_ECU
 SG_ Loc_SNR_49_001 : 15|11@1+ (0.0625,0) [0|40] "dB"  Central_ECU
 SG_ Loc_RadialDist_49_001 : 0|15@1+ (0.0078125,0) [0|250] "m"  Central_ECU

BO_ 328 Location_Data_48: 64 Radar
 SG_ Loc_ElevAngleQly_48_004 : 416|8@1+ (1,0) [0|255] ""  Central_ECU
 SG_ Loc_ElevAngleQly_48_003 : 392|8@1+ (1,0) [0|255] ""  Central_ECU
 SG_ Loc_ElevAngleQly_48_002 : 368|8@1+ (1,0) [0|255] ""  Central_ECU
 SG_ Loc_ElevAngleQly_48_001 : 344|8@1+ (1,0) [0|255] ""  Central_ECU
 SG_ Loc_AziAngleQly_48_004 : 408|8@1+ (1,0) [0|255] ""  Central_ECU
 SG_ Loc_AziAngleQly_48_003 : 384|8@1+ (1,0) [0|255] ""  Central_ECU
 SG_ Loc_AziAngleQly_48_002 : 360|8@1+ (1,0) [0|255] ""  Central_ECU
 SG_ Loc_AziAngleQly_48_001 : 336|8@1+ (1,0) [0|255] ""  Central_ECU
 SG_ Loc_RadialDistVeloQly_48_004 : 400|8@1+ (1,0) [0|255] ""  Central_ECU
 SG_ Loc_RadialDistVeloQly_48_003 : 376|8@1+ (1,0) [0|255] ""  Central_ECU
 SG_ Loc_RadialDistVeloQly_48_002 : 352|8@1+ (1,0) [0|255] ""  Central_ECU
 SG_ Loc_RadialDistVeloQly_48_001 : 328|8@1+ (1,0) [0|255] ""  Central_ECU
 SG_ Loc_Validity_48_004 : 327|1@1+ (1,0) [0|1] ""  Central_ECU
 SG_ Loc_Validity_48_003 : 326|1@1+ (1,0) [0|1] ""  Central_ECU
 SG_ Loc_Validity_48_002 : 325|1@1+ (1,0) [0|1] ""  Central_ECU
 SG_ Loc_Validity_48_001 : 324|1@1+ (1,0) [0|1] ""  Central_ECU
 SG_ Loc_48_Blockcnt : 320|4@1+ (1,0) [0|15] ""  Central_ECU
 SG_ Loc_48_CRC : 296|16@1+ (1,0) [0|65535] ""  Central_ECU
 SG_ Loc_48_AliveCtr : 312|8@1+ (1,0) [0|255] ""  Central_ECU
 SG_ Loc_SNR_48_004 : 237|11@1+ (0.0625,0) [0|40] "dB"  Central_ECU
 SG_ Loc_SNR_48_003 : 163|11@1+ (0.0625,0) [0|40] "dB"  Central_ECU
 SG_ Loc_SNR_48_002 : 89|11@1+ (0.0625,0) [0|40] "dB"  Central_ECU
 SG_ Loc_RCS_48_004 : 286|10@1+ (0.125,-50) [-50|70] "dBm^2"  Central_ECU
 SG_ Loc_RCS_48_003 : 212|10@1+ (0.125,-50) [-50|70] "dBm^2"  Central_ECU
 SG_ Loc_RCS_48_002 : 138|10@1+ (0.125,-50) [-50|70] "dBm^2"  Central_ECU
 SG_ Loc_RadialVelo_48_004 : 248|15@1+ (0.0078125,-128) [-128|127] "m/s"  Central_ECU
 SG_ Loc_RadialVelo_48_003 : 174|15@1+ (0.0078125,-128) [-128|127] "m/s"  Central_ECU
 SG_ Loc_RadialVelo_48_002 : 100|15@1+ (0.0078125,-128) [-128|127] "m/s"  Central_ECU
 SG_ Loc_RadialDist_48_004 : 222|15@1+ (0.0078125,0) [0|250] "m"  Central_ECU
 SG_ Loc_RadialDist_48_003 : 148|15@1+ (0.0078125,0) [0|250] "m"  Central_ECU
 SG_ Loc_RadialDist_48_002 : 74|15@1+ (0.0078125,0) [0|250] "m"  Central_ECU
 SG_ Loc_ElevAngle_48_004 : 275|11@1+ (0.001,-0.785) [-0.785|0.785] "rad"  Central_ECU
 SG_ Loc_ElevAngle_48_003 : 201|11@1+ (0.001,-0.785) [-0.785|0.785] "rad"  Central_ECU
 SG_ Loc_ElevAngle_48_002 : 127|11@1+ (0.001,-0.785) [-0.785|0.785] "rad"  Central_ECU
 SG_ Loc_AziAngle_48_004 : 263|12@1+ (0.001,-1.57) [-1.57|1.57] "rad"  Central_ECU
 SG_ Loc_AziAngle_48_003 : 189|12@1+ (0.001,-1.57) [-1.57|1.57] "rad"  Central_ECU
 SG_ Loc_AziAngle_48_002 : 115|12@1+ (0.001,-1.57) [-1.57|1.57] "rad"  Central_ECU
 SG_ Loc_RCS_48_001 : 64|10@1+ (0.125,-50) [-50|70] "dBm^2"  Central_ECU
 SG_ Loc_ElevAngle_48_001 : 53|11@1+ (0.001,-0.785) [-0.785|0.785] "rad"  Central_ECU
 SG_ Loc_AziAngle_48_001 : 41|12@1+ (0.001,-1.57) [-1.57|1.57] "rad"  Central_ECU
 SG_ Loc_RadialVelo_48_001 : 26|15@1+ (0.0078125,-128) [-128|127] "m/s"  Central_ECU
 SG_ Loc_SNR_48_001 : 15|11@1+ (0.0625,0) [0|40] "dB"  Central_ECU
 SG_ Loc_RadialDist_48_001 : 0|15@1+ (0.0078125,0) [0|250] "m"  Central_ECU

BO_ 327 Location_Data_47: 64 Radar
 SG_ Loc_ElevAngleQly_47_004 : 416|8@1+ (1,0) [0|255] ""  Central_ECU
 SG_ Loc_ElevAngleQly_47_003 : 392|8@1+ (1,0) [0|255] ""  Central_ECU
 SG_ Loc_ElevAngleQly_47_002 : 368|8@1+ (1,0) [0|255] ""  Central_ECU
 SG_ Loc_ElevAngleQly_47_001 : 344|8@1+ (1,0) [0|255] ""  Central_ECU
 SG_ Loc_AziAngleQly_47_004 : 408|8@1+ (1,0) [0|255] ""  Central_ECU
 SG_ Loc_AziAngleQly_47_003 : 384|8@1+ (1,0) [0|255] ""  Central_ECU
 SG_ Loc_AziAngleQly_47_002 : 360|8@1+ (1,0) [0|255] ""  Central_ECU
 SG_ Loc_AziAngleQly_47_001 : 336|8@1+ (1,0) [0|255] ""  Central_ECU
 SG_ Loc_RadialDistVeloQly_47_004 : 400|8@1+ (1,0) [0|255] ""  Central_ECU
 SG_ Loc_RadialDistVeloQly_47_003 : 376|8@1+ (1,0) [0|255] ""  Central_ECU
 SG_ Loc_RadialDistVeloQly_47_002 : 352|8@1+ (1,0) [0|255] ""  Central_ECU
 SG_ Loc_RadialDistVeloQly_47_001 : 328|8@1+ (1,0) [0|255] ""  Central_ECU
 SG_ Loc_Validity_47_004 : 327|1@1+ (1,0) [0|1] ""  Central_ECU
 SG_ Loc_Validity_47_003 : 326|1@1+ (1,0) [0|1] ""  Central_ECU
 SG_ Loc_Validity_47_002 : 325|1@1+ (1,0) [0|1] ""  Central_ECU
 SG_ Loc_Validity_47_001 : 324|1@1+ (1,0) [0|1] ""  Central_ECU
 SG_ Loc_47_Blockcnt : 320|4@1+ (1,0) [0|15] ""  Central_ECU
 SG_ Loc_47_CRC : 296|16@1+ (1,0) [0|65535] ""  Central_ECU
 SG_ Loc_47_AliveCtr : 312|8@1+ (1,0) [0|255] ""  Central_ECU
 SG_ Loc_SNR_47_004 : 237|11@1+ (0.0625,0) [0|40] "dB"  Central_ECU
 SG_ Loc_SNR_47_003 : 163|11@1+ (0.0625,0) [0|40] "dB"  Central_ECU
 SG_ Loc_SNR_47_002 : 89|11@1+ (0.0625,0) [0|40] "dB"  Central_ECU
 SG_ Loc_RCS_47_004 : 286|10@1+ (0.125,-50) [-50|70] "dBm^2"  Central_ECU
 SG_ Loc_RCS_47_003 : 212|10@1+ (0.125,-50) [-50|70] "dBm^2"  Central_ECU
 SG_ Loc_RCS_47_002 : 138|10@1+ (0.125,-50) [-50|70] "dBm^2"  Central_ECU
 SG_ Loc_RadialVelo_47_004 : 248|15@1+ (0.0078125,-128) [-128|127] "m/s"  Central_ECU
 SG_ Loc_RadialVelo_47_003 : 174|15@1+ (0.0078125,-128) [-128|127] "m/s"  Central_ECU
 SG_ Loc_RadialVelo_47_002 : 100|15@1+ (0.0078125,-128) [-128|127] "m/s"  Central_ECU
 SG_ Loc_RadialDist_47_004 : 222|15@1+ (0.0078125,0) [0|250] "m"  Central_ECU
 SG_ Loc_RadialDist_47_003 : 148|15@1+ (0.0078125,0) [0|250] "m"  Central_ECU
 SG_ Loc_RadialDist_47_002 : 74|15@1+ (0.0078125,0) [0|250] "m"  Central_ECU
 SG_ Loc_ElevAngle_47_004 : 275|11@1+ (0.001,-0.785) [-0.785|0.785] "rad"  Central_ECU
 SG_ Loc_ElevAngle_47_003 : 201|11@1+ (0.001,-0.785) [-0.785|0.785] "rad"  Central_ECU
 SG_ Loc_ElevAngle_47_002 : 127|11@1+ (0.001,-0.785) [-0.785|0.785] "rad"  Central_ECU
 SG_ Loc_AziAngle_47_004 : 263|12@1+ (0.001,-1.57) [-1.57|1.57] "rad"  Central_ECU
 SG_ Loc_AziAngle_47_003 : 189|12@1+ (0.001,-1.57) [-1.57|1.57] "rad"  Central_ECU
 SG_ Loc_AziAngle_47_002 : 115|12@1+ (0.001,-1.57) [-1.57|1.57] "rad"  Central_ECU
 SG_ Loc_RCS_47_001 : 64|10@1+ (0.125,-50) [-50|70] "dBm^2"  Central_ECU
 SG_ Loc_ElevAngle_47_001 : 53|11@1+ (0.001,-0.785) [-0.785|0.785] "rad"  Central_ECU
 SG_ Loc_AziAngle_47_001 : 41|12@1+ (0.001,-1.57) [-1.57|1.57] "rad"  Central_ECU
 SG_ Loc_RadialVelo_47_001 : 26|15@1+ (0.0078125,-128) [-128|127] "m/s"  Central_ECU
 SG_ Loc_SNR_47_001 : 15|11@1+ (0.0625,0) [0|40] "dB"  Central_ECU
 SG_ Loc_RadialDist_47_001 : 0|15@1+ (0.0078125,0) [0|250] "m"  Central_ECU

BO_ 326 Location_Data_46: 64 Radar
 SG_ Loc_ElevAngleQly_46_004 : 416|8@1+ (1,0) [0|255] ""  Central_ECU
 SG_ Loc_ElevAngleQly_46_003 : 392|8@1+ (1,0) [0|255] ""  Central_ECU
 SG_ Loc_ElevAngleQly_46_002 : 368|8@1+ (1,0) [0|255] ""  Central_ECU
 SG_ Loc_ElevAngleQly_46_001 : 344|8@1+ (1,0) [0|255] ""  Central_ECU
 SG_ Loc_AziAngleQly_46_004 : 408|8@1+ (1,0) [0|255] ""  Central_ECU
 SG_ Loc_AziAngleQly_46_003 : 384|8@1+ (1,0) [0|255] ""  Central_ECU
 SG_ Loc_AziAngleQly_46_002 : 360|8@1+ (1,0) [0|255] ""  Central_ECU
 SG_ Loc_AziAngleQly_46_001 : 336|8@1+ (1,0) [0|255] ""  Central_ECU
 SG_ Loc_RadialDistVeloQly_46_004 : 400|8@1+ (1,0) [0|255] ""  Central_ECU
 SG_ Loc_RadialDistVeloQly_46_003 : 376|8@1+ (1,0) [0|255] ""  Central_ECU
 SG_ Loc_RadialDistVeloQly_46_002 : 352|8@1+ (1,0) [0|255] ""  Central_ECU
 SG_ Loc_RadialDistVeloQly_46_001 : 328|8@1+ (1,0) [0|255] ""  Central_ECU
 SG_ Loc_Validity_46_004 : 327|1@1+ (1,0) [0|1] ""  Central_ECU
 SG_ Loc_Validity_46_003 : 326|1@1+ (1,0) [0|1] ""  Central_ECU
 SG_ Loc_Validity_46_002 : 325|1@1+ (1,0) [0|1] ""  Central_ECU
 SG_ Loc_Validity_46_001 : 324|1@1+ (1,0) [0|1] ""  Central_ECU
 SG_ Loc_46_Blockcnt : 320|4@1+ (1,0) [0|15] ""  Central_ECU
 SG_ Loc_46_CRC : 296|16@1+ (1,0) [0|65535] ""  Central_ECU
 SG_ Loc_46_AliveCtr : 312|8@1+ (1,0) [0|255] ""  Central_ECU
 SG_ Loc_SNR_46_004 : 237|11@1+ (0.0625,0) [0|40] "dB"  Central_ECU
 SG_ Loc_SNR_46_003 : 163|11@1+ (0.0625,0) [0|40] "dB"  Central_ECU
 SG_ Loc_SNR_46_002 : 89|11@1+ (0.0625,0) [0|40] "dB"  Central_ECU
 SG_ Loc_RCS_46_004 : 286|10@1+ (0.125,-50) [-50|70] "dBm^2"  Central_ECU
 SG_ Loc_RCS_46_003 : 212|10@1+ (0.125,-50) [-50|70] "dBm^2"  Central_ECU
 SG_ Loc_RCS_46_002 : 138|10@1+ (0.125,-50) [-50|70] "dBm^2"  Central_ECU
 SG_ Loc_RadialVelo_46_004 : 248|15@1+ (0.0078125,-128) [-128|127] "m/s"  Central_ECU
 SG_ Loc_RadialVelo_46_003 : 174|15@1+ (0.0078125,-128) [-128|127] "m/s"  Central_ECU
 SG_ Loc_RadialVelo_46_002 : 100|15@1+ (0.0078125,-128) [-128|127] "m/s"  Central_ECU
 SG_ Loc_RadialDist_46_004 : 222|15@1+ (0.0078125,0) [0|250] "m"  Central_ECU
 SG_ Loc_RadialDist_46_003 : 148|15@1+ (0.0078125,0) [0|250] "m"  Central_ECU
 SG_ Loc_RadialDist_46_002 : 74|15@1+ (0.0078125,0) [0|250] "m"  Central_ECU
 SG_ Loc_ElevAngle_46_004 : 275|11@1+ (0.001,-0.785) [-0.785|0.785] "rad"  Central_ECU
 SG_ Loc_ElevAngle_46_003 : 201|11@1+ (0.001,-0.785) [-0.785|0.785] "rad"  Central_ECU
 SG_ Loc_ElevAngle_46_002 : 127|11@1+ (0.001,-0.785) [-0.785|0.785] "rad"  Central_ECU
 SG_ Loc_AziAngle_46_004 : 263|12@1+ (0.001,-1.57) [-1.57|1.57] "rad"  Central_ECU
 SG_ Loc_AziAngle_46_003 : 189|12@1+ (0.001,-1.57) [-1.57|1.57] "rad"  Central_ECU
 SG_ Loc_AziAngle_46_002 : 115|12@1+ (0.001,-1.57) [-1.57|1.57] "rad"  Central_ECU
 SG_ Loc_RCS_46_001 : 64|10@1+ (0.125,-50) [-50|70] "dBm^2"  Central_ECU
 SG_ Loc_ElevAngle_46_001 : 53|11@1+ (0.001,-0.785) [-0.785|0.785] "rad"  Central_ECU
 SG_ Loc_AziAngle_46_001 : 41|12@1+ (0.001,-1.57) [-1.57|1.57] "rad"  Central_ECU
 SG_ Loc_RadialVelo_46_001 : 26|15@1+ (0.0078125,-128) [-128|127] "m/s"  Central_ECU
 SG_ Loc_SNR_46_001 : 15|11@1+ (0.0625,0) [0|40] "dB"  Central_ECU
 SG_ Loc_RadialDist_46_001 : 0|15@1+ (0.0078125,0) [0|250] "m"  Central_ECU

BO_ 325 Location_Data_45: 64 Radar
 SG_ Loc_ElevAngleQly_45_004 : 416|8@1+ (1,0) [0|255] ""  Central_ECU
 SG_ Loc_ElevAngleQly_45_003 : 392|8@1+ (1,0) [0|255] ""  Central_ECU
 SG_ Loc_ElevAngleQly_45_002 : 368|8@1+ (1,0) [0|255] ""  Central_ECU
 SG_ Loc_ElevAngleQly_45_001 : 344|8@1+ (1,0) [0|255] ""  Central_ECU
 SG_ Loc_AziAngleQly_45_004 : 408|8@1+ (1,0) [0|255] ""  Central_ECU
 SG_ Loc_AziAngleQly_45_003 : 384|8@1+ (1,0) [0|255] ""  Central_ECU
 SG_ Loc_AziAngleQly_45_002 : 360|8@1+ (1,0) [0|255] ""  Central_ECU
 SG_ Loc_AziAngleQly_45_001 : 336|8@1+ (1,0) [0|255] ""  Central_ECU
 SG_ Loc_RadialDistVeloQly_45_004 : 400|8@1+ (1,0) [0|255] ""  Central_ECU
 SG_ Loc_RadialDistVeloQly_45_003 : 376|8@1+ (1,0) [0|255] ""  Central_ECU
 SG_ Loc_RadialDistVeloQly_45_002 : 352|8@1+ (1,0) [0|255] ""  Central_ECU
 SG_ Loc_RadialDistVeloQly_45_001 : 328|8@1+ (1,0) [0|255] ""  Central_ECU
 SG_ Loc_Validity_45_004 : 327|1@1+ (1,0) [0|1] ""  Central_ECU
 SG_ Loc_Validity_45_003 : 326|1@1+ (1,0) [0|1] ""  Central_ECU
 SG_ Loc_Validity_45_002 : 325|1@1+ (1,0) [0|1] ""  Central_ECU
 SG_ Loc_Validity_45_001 : 324|1@1+ (1,0) [0|1] ""  Central_ECU
 SG_ Loc_45_Blockcnt : 320|4@1+ (1,0) [0|15] ""  Central_ECU
 SG_ Loc_45_CRC : 296|16@1+ (1,0) [0|65535] ""  Central_ECU
 SG_ Loc_45_AliveCtr : 312|8@1+ (1,0) [0|255] ""  Central_ECU
 SG_ Loc_SNR_45_004 : 237|11@1+ (0.0625,0) [0|40] "dB"  Central_ECU
 SG_ Loc_SNR_45_003 : 163|11@1+ (0.0625,0) [0|40] "dB"  Central_ECU
 SG_ Loc_SNR_45_002 : 89|11@1+ (0.0625,0) [0|40] "dB"  Central_ECU
 SG_ Loc_RCS_45_004 : 286|10@1+ (0.125,-50) [-50|70] "dBm^2"  Central_ECU
 SG_ Loc_RCS_45_003 : 212|10@1+ (0.125,-50) [-50|70] "dBm^2"  Central_ECU
 SG_ Loc_RCS_45_002 : 138|10@1+ (0.125,-50) [-50|70] "dBm^2"  Central_ECU
 SG_ Loc_RadialVelo_45_004 : 248|15@1+ (0.0078125,-128) [-128|127] "m/s"  Central_ECU
 SG_ Loc_RadialVelo_45_003 : 174|15@1+ (0.0078125,-128) [-128|127] "m/s"  Central_ECU
 SG_ Loc_RadialVelo_45_002 : 100|15@1+ (0.0078125,-128) [-128|127] "m/s"  Central_ECU
 SG_ Loc_RadialDist_45_004 : 222|15@1+ (0.0078125,0) [0|250] "m"  Central_ECU
 SG_ Loc_RadialDist_45_003 : 148|15@1+ (0.0078125,0) [0|250] "m"  Central_ECU
 SG_ Loc_RadialDist_45_002 : 74|15@1+ (0.0078125,0) [0|250] "m"  Central_ECU
 SG_ Loc_ElevAngle_45_004 : 275|11@1+ (0.001,-0.785) [-0.785|0.785] "rad"  Central_ECU
 SG_ Loc_ElevAngle_45_003 : 201|11@1+ (0.001,-0.785) [-0.785|0.785] "rad"  Central_ECU
 SG_ Loc_ElevAngle_45_002 : 127|11@1+ (0.001,-0.785) [-0.785|0.785] "rad"  Central_ECU
 SG_ Loc_AziAngle_45_004 : 263|12@1+ (0.001,-1.57) [-1.57|1.57] "rad"  Central_ECU
 SG_ Loc_AziAngle_45_003 : 189|12@1+ (0.001,-1.57) [-1.57|1.57] "rad"  Central_ECU
 SG_ Loc_AziAngle_45_002 : 115|12@1+ (0.001,-1.57) [-1.57|1.57] "rad"  Central_ECU
 SG_ Loc_RCS_45_001 : 64|10@1+ (0.125,-50) [-50|70] "dBm^2"  Central_ECU
 SG_ Loc_ElevAngle_45_001 : 53|11@1+ (0.001,-0.785) [-0.785|0.785] "rad"  Central_ECU
 SG_ Loc_AziAngle_45_001 : 41|12@1+ (0.001,-1.57) [-1.57|1.57] "rad"  Central_ECU
 SG_ Loc_RadialVelo_45_001 : 26|15@1+ (0.0078125,-128) [-128|127] "m/s"  Central_ECU
 SG_ Loc_SNR_45_001 : 15|11@1+ (0.0625,0) [0|40] "dB"  Central_ECU
 SG_ Loc_RadialDist_45_001 : 0|15@1+ (0.0078125,0) [0|250] "m"  Central_ECU

BO_ 324 Location_Data_44: 64 Radar
 SG_ Loc_ElevAngleQly_44_004 : 416|8@1+ (1,0) [0|255] ""  Central_ECU
 SG_ Loc_ElevAngleQly_44_003 : 392|8@1+ (1,0) [0|255] ""  Central_ECU
 SG_ Loc_ElevAngleQly_44_002 : 368|8@1+ (1,0) [0|255] ""  Central_ECU
 SG_ Loc_ElevAngleQly_44_001 : 344|8@1+ (1,0) [0|255] ""  Central_ECU
 SG_ Loc_AziAngleQly_44_004 : 408|8@1+ (1,0) [0|255] ""  Central_ECU
 SG_ Loc_AziAngleQly_44_003 : 384|8@1+ (1,0) [0|255] ""  Central_ECU
 SG_ Loc_AziAngleQly_44_002 : 360|8@1+ (1,0) [0|255] ""  Central_ECU
 SG_ Loc_AziAngleQly_44_001 : 336|8@1+ (1,0) [0|255] ""  Central_ECU
 SG_ Loc_RadialDistVeloQly_44_004 : 400|8@1+ (1,0) [0|255] ""  Central_ECU
 SG_ Loc_RadialDistVeloQly_44_003 : 376|8@1+ (1,0) [0|255] ""  Central_ECU
 SG_ Loc_RadialDistVeloQly_44_002 : 352|8@1+ (1,0) [0|255] ""  Central_ECU
 SG_ Loc_RadialDistVeloQly_44_001 : 328|8@1+ (1,0) [0|255] ""  Central_ECU
 SG_ Loc_Validity_44_004 : 327|1@1+ (1,0) [0|1] ""  Central_ECU
 SG_ Loc_Validity_44_003 : 326|1@1+ (1,0) [0|1] ""  Central_ECU
 SG_ Loc_Validity_44_002 : 325|1@1+ (1,0) [0|1] ""  Central_ECU
 SG_ Loc_Validity_44_001 : 324|1@1+ (1,0) [0|1] ""  Central_ECU
 SG_ Loc_44_Blockcnt : 320|4@1+ (1,0) [0|15] ""  Central_ECU
 SG_ Loc_44_CRC : 296|16@1+ (1,0) [0|65535] ""  Central_ECU
 SG_ Loc_44_AliveCtr : 312|8@1+ (1,0) [0|255] ""  Central_ECU
 SG_ Loc_SNR_44_004 : 237|11@1+ (0.0625,0) [0|40] "dB"  Central_ECU
 SG_ Loc_SNR_44_003 : 163|11@1+ (0.0625,0) [0|40] "dB"  Central_ECU
 SG_ Loc_SNR_44_002 : 89|11@1+ (0.0625,0) [0|40] "dB"  Central_ECU
 SG_ Loc_RCS_44_004 : 286|10@1+ (0.125,-50) [-50|70] "dBm^2"  Central_ECU
 SG_ Loc_RCS_44_003 : 212|10@1+ (0.125,-50) [-50|70] "dBm^2"  Central_ECU
 SG_ Loc_RCS_44_002 : 138|10@1+ (0.125,-50) [-50|70] "dBm^2"  Central_ECU
 SG_ Loc_RadialVelo_44_004 : 248|15@1+ (0.0078125,-128) [-128|127] "m/s"  Central_ECU
 SG_ Loc_RadialVelo_44_003 : 174|15@1+ (0.0078125,-128) [-128|127] "m/s"  Central_ECU
 SG_ Loc_RadialVelo_44_002 : 100|15@1+ (0.0078125,-128) [-128|127] "m/s"  Central_ECU
 SG_ Loc_RadialDist_44_004 : 222|15@1+ (0.0078125,0) [0|250] "m"  Central_ECU
 SG_ Loc_RadialDist_44_003 : 148|15@1+ (0.0078125,0) [0|250] "m"  Central_ECU
 SG_ Loc_RadialDist_44_002 : 74|15@1+ (0.0078125,0) [0|250] "m"  Central_ECU
 SG_ Loc_ElevAngle_44_004 : 275|11@1+ (0.001,-0.785) [-0.785|0.785] "rad"  Central_ECU
 SG_ Loc_ElevAngle_44_003 : 201|11@1+ (0.001,-0.785) [-0.785|0.785] "rad"  Central_ECU
 SG_ Loc_ElevAngle_44_002 : 127|11@1+ (0.001,-0.785) [-0.785|0.785] "rad"  Central_ECU
 SG_ Loc_AziAngle_44_004 : 263|12@1+ (0.001,-1.57) [-1.57|1.57] "rad"  Central_ECU
 SG_ Loc_AziAngle_44_003 : 189|12@1+ (0.001,-1.57) [-1.57|1.57] "rad"  Central_ECU
 SG_ Loc_AziAngle_44_002 : 115|12@1+ (0.001,-1.57) [-1.57|1.57] "rad"  Central_ECU
 SG_ Loc_RCS_44_001 : 64|10@1+ (0.125,-50) [-50|70] "dBm^2"  Central_ECU
 SG_ Loc_ElevAngle_44_001 : 53|11@1+ (0.001,-0.785) [-0.785|0.785] "rad"  Central_ECU
 SG_ Loc_AziAngle_44_001 : 41|12@1+ (0.001,-1.57) [-1.57|1.57] "rad"  Central_ECU
 SG_ Loc_RadialVelo_44_001 : 26|15@1+ (0.0078125,-128) [-128|127] "m/s"  Central_ECU
 SG_ Loc_SNR_44_001 : 15|11@1+ (0.0625,0) [0|40] "dB"  Central_ECU
 SG_ Loc_RadialDist_44_001 : 0|15@1+ (0.0078125,0) [0|250] "m"  Central_ECU

BO_ 323 Location_Data_43: 64 Radar
 SG_ Loc_ElevAngleQly_43_004 : 416|8@1+ (1,0) [0|255] ""  Central_ECU
 SG_ Loc_ElevAngleQly_43_003 : 392|8@1+ (1,0) [0|255] ""  Central_ECU
 SG_ Loc_ElevAngleQly_43_002 : 368|8@1+ (1,0) [0|255] ""  Central_ECU
 SG_ Loc_ElevAngleQly_43_001 : 344|8@1+ (1,0) [0|255] ""  Central_ECU
 SG_ Loc_AziAngleQly_43_004 : 408|8@1+ (1,0) [0|255] ""  Central_ECU
 SG_ Loc_AziAngleQly_43_003 : 384|8@1+ (1,0) [0|255] ""  Central_ECU
 SG_ Loc_AziAngleQly_43_002 : 360|8@1+ (1,0) [0|255] ""  Central_ECU
 SG_ Loc_AziAngleQly_43_001 : 336|8@1+ (1,0) [0|255] ""  Central_ECU
 SG_ Loc_RadialDistVeloQly_43_004 : 400|8@1+ (1,0) [0|255] ""  Central_ECU
 SG_ Loc_RadialDistVeloQly_43_003 : 376|8@1+ (1,0) [0|255] ""  Central_ECU
 SG_ Loc_RadialDistVeloQly_43_002 : 352|8@1+ (1,0) [0|255] ""  Central_ECU
 SG_ Loc_RadialDistVeloQly_43_001 : 328|8@1+ (1,0) [0|255] ""  Central_ECU
 SG_ Loc_Validity_43_004 : 327|1@1+ (1,0) [0|1] ""  Central_ECU
 SG_ Loc_Validity_43_003 : 326|1@1+ (1,0) [0|1] ""  Central_ECU
 SG_ Loc_Validity_43_002 : 325|1@1+ (1,0) [0|1] ""  Central_ECU
 SG_ Loc_Validity_43_001 : 324|1@1+ (1,0) [0|1] ""  Central_ECU
 SG_ Loc_43_Blockcnt : 320|4@1+ (1,0) [0|15] ""  Central_ECU
 SG_ Loc_43_CRC : 296|16@1+ (1,0) [0|65535] ""  Central_ECU
 SG_ Loc_43_AliveCtr : 312|8@1+ (1,0) [0|255] ""  Central_ECU
 SG_ Loc_SNR_43_004 : 237|11@1+ (0.0625,0) [0|40] "dB"  Central_ECU
 SG_ Loc_SNR_43_003 : 163|11@1+ (0.0625,0) [0|40] "dB"  Central_ECU
 SG_ Loc_SNR_43_002 : 89|11@1+ (0.0625,0) [0|40] "dB"  Central_ECU
 SG_ Loc_RCS_43_004 : 286|10@1+ (0.125,-50) [-50|70] "dBm^2"  Central_ECU
 SG_ Loc_RCS_43_003 : 212|10@1+ (0.125,-50) [-50|70] "dBm^2"  Central_ECU
 SG_ Loc_RCS_43_002 : 138|10@1+ (0.125,-50) [-50|70] "dBm^2"  Central_ECU
 SG_ Loc_RadialVelo_43_004 : 248|15@1+ (0.0078125,-128) [-128|127] "m/s"  Central_ECU
 SG_ Loc_RadialVelo_43_003 : 174|15@1+ (0.0078125,-128) [-128|127] "m/s"  Central_ECU
 SG_ Loc_RadialVelo_43_002 : 100|15@1+ (0.0078125,-128) [-128|127] "m/s"  Central_ECU
 SG_ Loc_RadialDist_43_004 : 222|15@1+ (0.0078125,0) [0|250] "m"  Central_ECU
 SG_ Loc_RadialDist_43_003 : 148|15@1+ (0.0078125,0) [0|250] "m"  Central_ECU
 SG_ Loc_RadialDist_43_002 : 74|15@1+ (0.0078125,0) [0|250] "m"  Central_ECU
 SG_ Loc_ElevAngle_43_004 : 275|11@1+ (0.001,-0.785) [-0.785|0.785] "rad"  Central_ECU
 SG_ Loc_ElevAngle_43_003 : 201|11@1+ (0.001,-0.785) [-0.785|0.785] "rad"  Central_ECU
 SG_ Loc_ElevAngle_43_002 : 127|11@1+ (0.001,-0.785) [-0.785|0.785] "rad"  Central_ECU
 SG_ Loc_AziAngle_43_004 : 263|12@1+ (0.001,-1.57) [-1.57|1.57] "rad"  Central_ECU
 SG_ Loc_AziAngle_43_003 : 189|12@1+ (0.001,-1.57) [-1.57|1.57] "rad"  Central_ECU
 SG_ Loc_AziAngle_43_002 : 115|12@1+ (0.001,-1.57) [-1.57|1.57] "rad"  Central_ECU
 SG_ Loc_RCS_43_001 : 64|10@1+ (0.125,-50) [-50|70] "dBm^2"  Central_ECU
 SG_ Loc_ElevAngle_43_001 : 53|11@1+ (0.001,-0.785) [-0.785|0.785] "rad"  Central_ECU
 SG_ Loc_AziAngle_43_001 : 41|12@1+ (0.001,-1.57) [-1.57|1.57] "rad"  Central_ECU
 SG_ Loc_RadialVelo_43_001 : 26|15@1+ (0.0078125,-128) [-128|127] "m/s"  Central_ECU
 SG_ Loc_SNR_43_001 : 15|11@1+ (0.0625,0) [0|40] "dB"  Central_ECU
 SG_ Loc_RadialDist_43_001 : 0|15@1+ (0.0078125,0) [0|250] "m"  Central_ECU

BO_ 322 Location_Data_42: 64 Radar
 SG_ Loc_ElevAngleQly_42_004 : 416|8@1+ (1,0) [0|255] ""  Central_ECU
 SG_ Loc_ElevAngleQly_42_003 : 392|8@1+ (1,0) [0|255] ""  Central_ECU
 SG_ Loc_ElevAngleQly_42_002 : 368|8@1+ (1,0) [0|255] ""  Central_ECU
 SG_ Loc_ElevAngleQly_42_001 : 344|8@1+ (1,0) [0|255] ""  Central_ECU
 SG_ Loc_AziAngleQly_42_004 : 408|8@1+ (1,0) [0|255] ""  Central_ECU
 SG_ Loc_AziAngleQly_42_003 : 384|8@1+ (1,0) [0|255] ""  Central_ECU
 SG_ Loc_AziAngleQly_42_002 : 360|8@1+ (1,0) [0|255] ""  Central_ECU
 SG_ Loc_AziAngleQly_42_001 : 336|8@1+ (1,0) [0|255] ""  Central_ECU
 SG_ Loc_RadialDistVeloQly_42_004 : 400|8@1+ (1,0) [0|255] ""  Central_ECU
 SG_ Loc_RadialDistVeloQly_42_003 : 376|8@1+ (1,0) [0|255] ""  Central_ECU
 SG_ Loc_RadialDistVeloQly_42_002 : 352|8@1+ (1,0) [0|255] ""  Central_ECU
 SG_ Loc_RadialDistVeloQly_42_001 : 328|8@1+ (1,0) [0|255] ""  Central_ECU
 SG_ Loc_Validity_42_004 : 327|1@1+ (1,0) [0|1] ""  Central_ECU
 SG_ Loc_Validity_42_003 : 326|1@1+ (1,0) [0|1] ""  Central_ECU
 SG_ Loc_Validity_42_002 : 325|1@1+ (1,0) [0|1] ""  Central_ECU
 SG_ Loc_Validity_42_001 : 324|1@1+ (1,0) [0|1] ""  Central_ECU
 SG_ Loc_42_Blockcnt : 320|4@1+ (1,0) [0|15] ""  Central_ECU
 SG_ Loc_42_CRC : 296|16@1+ (1,0) [0|65535] ""  Central_ECU
 SG_ Loc_42_AliveCtr : 312|8@1+ (1,0) [0|255] ""  Central_ECU
 SG_ Loc_SNR_42_004 : 237|11@1+ (0.0625,0) [0|40] "dB"  Central_ECU
 SG_ Loc_SNR_42_003 : 163|11@1+ (0.0625,0) [0|40] "dB"  Central_ECU
 SG_ Loc_SNR_42_002 : 89|11@1+ (0.0625,0) [0|40] "dB"  Central_ECU
 SG_ Loc_RCS_42_004 : 286|10@1+ (0.125,-50) [-50|70] "dBm^2"  Central_ECU
 SG_ Loc_RCS_42_003 : 212|10@1+ (0.125,-50) [-50|70] "dBm^2"  Central_ECU
 SG_ Loc_RCS_42_002 : 138|10@1+ (0.125,-50) [-50|70] "dBm^2"  Central_ECU
 SG_ Loc_RadialVelo_42_004 : 248|15@1+ (0.0078125,-128) [-128|127] "m/s"  Central_ECU
 SG_ Loc_RadialVelo_42_003 : 174|15@1+ (0.0078125,-128) [-128|127] "m/s"  Central_ECU
 SG_ Loc_RadialVelo_42_002 : 100|15@1+ (0.0078125,-128) [-128|127] "m/s"  Central_ECU
 SG_ Loc_RadialDist_42_004 : 222|15@1+ (0.0078125,0) [0|250] "m"  Central_ECU
 SG_ Loc_RadialDist_42_003 : 148|15@1+ (0.0078125,0) [0|250] "m"  Central_ECU
 SG_ Loc_RadialDist_42_002 : 74|15@1+ (0.0078125,0) [0|250] "m"  Central_ECU
 SG_ Loc_ElevAngle_42_004 : 275|11@1+ (0.001,-0.785) [-0.785|0.785] "rad"  Central_ECU
 SG_ Loc_ElevAngle_42_003 : 201|11@1+ (0.001,-0.785) [-0.785|0.785] "rad"  Central_ECU
 SG_ Loc_ElevAngle_42_002 : 127|11@1+ (0.001,-0.785) [-0.785|0.785] "rad"  Central_ECU
 SG_ Loc_AziAngle_42_004 : 263|12@1+ (0.001,-1.57) [-1.57|1.57] "rad"  Central_ECU
 SG_ Loc_AziAngle_42_003 : 189|12@1+ (0.001,-1.57) [-1.57|1.57] "rad"  Central_ECU
 SG_ Loc_AziAngle_42_002 : 115|12@1+ (0.001,-1.57) [-1.57|1.57] "rad"  Central_ECU
 SG_ Loc_RCS_42_001 : 64|10@1+ (0.125,-50) [-50|70] "dBm^2"  Central_ECU
 SG_ Loc_ElevAngle_42_001 : 53|11@1+ (0.001,-0.785) [-0.785|0.785] "rad"  Central_ECU
 SG_ Loc_AziAngle_42_001 : 41|12@1+ (0.001,-1.57) [-1.57|1.57] "rad"  Central_ECU
 SG_ Loc_RadialVelo_42_001 : 26|15@1+ (0.0078125,-128) [-128|127] "m/s"  Central_ECU
 SG_ Loc_SNR_42_001 : 15|11@1+ (0.0625,0) [0|40] "dB"  Central_ECU
 SG_ Loc_RadialDist_42_001 : 0|15@1+ (0.0078125,0) [0|250] "m"  Central_ECU

BO_ 321 Location_Data_41: 64 Radar
 SG_ Loc_ElevAngleQly_41_004 : 416|8@1+ (1,0) [0|255] ""  Central_ECU
 SG_ Loc_ElevAngleQly_41_003 : 392|8@1+ (1,0) [0|255] ""  Central_ECU
 SG_ Loc_ElevAngleQly_41_002 : 368|8@1+ (1,0) [0|255] ""  Central_ECU
 SG_ Loc_ElevAngleQly_41_001 : 344|8@1+ (1,0) [0|255] ""  Central_ECU
 SG_ Loc_AziAngleQly_41_004 : 408|8@1+ (1,0) [0|255] ""  Central_ECU
 SG_ Loc_AziAngleQly_41_003 : 384|8@1+ (1,0) [0|255] ""  Central_ECU
 SG_ Loc_AziAngleQly_41_002 : 360|8@1+ (1,0) [0|255] ""  Central_ECU
 SG_ Loc_AziAngleQly_41_001 : 336|8@1+ (1,0) [0|255] ""  Central_ECU
 SG_ Loc_RadialDistVeloQly_41_004 : 400|8@1+ (1,0) [0|255] ""  Central_ECU
 SG_ Loc_RadialDistVeloQly_41_003 : 376|8@1+ (1,0) [0|255] ""  Central_ECU
 SG_ Loc_RadialDistVeloQly_41_002 : 352|8@1+ (1,0) [0|255] ""  Central_ECU
 SG_ Loc_RadialDistVeloQly_41_001 : 328|8@1+ (1,0) [0|255] ""  Central_ECU
 SG_ Loc_Validity_41_004 : 327|1@1+ (1,0) [0|1] ""  Central_ECU
 SG_ Loc_Validity_41_003 : 326|1@1+ (1,0) [0|1] ""  Central_ECU
 SG_ Loc_Validity_41_002 : 325|1@1+ (1,0) [0|1] ""  Central_ECU
 SG_ Loc_Validity_41_001 : 324|1@1+ (1,0) [0|1] ""  Central_ECU
 SG_ Loc_41_Blockcnt : 320|4@1+ (1,0) [0|15] ""  Central_ECU
 SG_ Loc_41_CRC : 296|16@1+ (1,0) [0|65535] ""  Central_ECU
 SG_ Loc_41_AliveCtr : 312|8@1+ (1,0) [0|255] ""  Central_ECU
 SG_ Loc_SNR_41_004 : 237|11@1+ (0.0625,0) [0|40] "dB"  Central_ECU
 SG_ Loc_SNR_41_003 : 163|11@1+ (0.0625,0) [0|40] "dB"  Central_ECU
 SG_ Loc_SNR_41_002 : 89|11@1+ (0.0625,0) [0|40] "dB"  Central_ECU
 SG_ Loc_RCS_41_004 : 286|10@1+ (0.125,-50) [-50|70] "dBm^2"  Central_ECU
 SG_ Loc_RCS_41_003 : 212|10@1+ (0.125,-50) [-50|70] "dBm^2"  Central_ECU
 SG_ Loc_RCS_41_002 : 138|10@1+ (0.125,-50) [-50|70] "dBm^2"  Central_ECU
 SG_ Loc_RadialVelo_41_004 : 248|15@1+ (0.0078125,-128) [-128|127] "m/s"  Central_ECU
 SG_ Loc_RadialVelo_41_003 : 174|15@1+ (0.0078125,-128) [-128|127] "m/s"  Central_ECU
 SG_ Loc_RadialVelo_41_002 : 100|15@1+ (0.0078125,-128) [-128|127] "m/s"  Central_ECU
 SG_ Loc_RadialDist_41_004 : 222|15@1+ (0.0078125,0) [0|250] "m"  Central_ECU
 SG_ Loc_RadialDist_41_003 : 148|15@1+ (0.0078125,0) [0|250] "m"  Central_ECU
 SG_ Loc_RadialDist_41_002 : 74|15@1+ (0.0078125,0) [0|250] "m"  Central_ECU
 SG_ Loc_ElevAngle_41_004 : 275|11@1+ (0.001,-0.785) [-0.785|0.785] "rad"  Central_ECU
 SG_ Loc_ElevAngle_41_003 : 201|11@1+ (0.001,-0.785) [-0.785|0.785] "rad"  Central_ECU
 SG_ Loc_ElevAngle_41_002 : 127|11@1+ (0.001,-0.785) [-0.785|0.785] "rad"  Central_ECU
 SG_ Loc_AziAngle_41_004 : 263|12@1+ (0.001,-1.57) [-1.57|1.57] "rad"  Central_ECU
 SG_ Loc_AziAngle_41_003 : 189|12@1+ (0.001,-1.57) [-1.57|1.57] "rad"  Central_ECU
 SG_ Loc_AziAngle_41_002 : 115|12@1+ (0.001,-1.57) [-1.57|1.57] "rad"  Central_ECU
 SG_ Loc_RCS_41_001 : 64|10@1+ (0.125,-50) [-50|70] "dBm^2"  Central_ECU
 SG_ Loc_ElevAngle_41_001 : 53|11@1+ (0.001,-0.785) [-0.785|0.785] "rad"  Central_ECU
 SG_ Loc_AziAngle_41_001 : 41|12@1+ (0.001,-1.57) [-1.57|1.57] "rad"  Central_ECU
 SG_ Loc_RadialVelo_41_001 : 26|15@1+ (0.0078125,-128) [-128|127] "m/s"  Central_ECU
 SG_ Loc_SNR_41_001 : 15|11@1+ (0.0625,0) [0|40] "dB"  Central_ECU
 SG_ Loc_RadialDist_41_001 : 0|15@1+ (0.0078125,0) [0|250] "m"  Central_ECU

BO_ 320 Location_Data_40: 64 Radar
 SG_ Loc_ElevAngleQly_40_004 : 416|8@1+ (1,0) [0|255] ""  Central_ECU
 SG_ Loc_ElevAngleQly_40_003 : 392|8@1+ (1,0) [0|255] ""  Central_ECU
 SG_ Loc_ElevAngleQly_40_002 : 368|8@1+ (1,0) [0|255] ""  Central_ECU
 SG_ Loc_ElevAngleQly_40_001 : 344|8@1+ (1,0) [0|255] ""  Central_ECU
 SG_ Loc_AziAngleQly_40_004 : 408|8@1+ (1,0) [0|255] ""  Central_ECU
 SG_ Loc_AziAngleQly_40_003 : 384|8@1+ (1,0) [0|255] ""  Central_ECU
 SG_ Loc_AziAngleQly_40_002 : 360|8@1+ (1,0) [0|255] ""  Central_ECU
 SG_ Loc_AziAngleQly_40_001 : 336|8@1+ (1,0) [0|255] ""  Central_ECU
 SG_ Loc_RadialDistVeloQly_40_004 : 400|8@1+ (1,0) [0|255] ""  Central_ECU
 SG_ Loc_RadialDistVeloQly_40_003 : 376|8@1+ (1,0) [0|255] ""  Central_ECU
 SG_ Loc_RadialDistVeloQly_40_002 : 352|8@1+ (1,0) [0|255] ""  Central_ECU
 SG_ Loc_RadialDistVeloQly_40_001 : 328|8@1+ (1,0) [0|255] ""  Central_ECU
 SG_ Loc_Validity_40_004 : 327|1@1+ (1,0) [0|1] ""  Central_ECU
 SG_ Loc_Validity_40_003 : 326|1@1+ (1,0) [0|1] ""  Central_ECU
 SG_ Loc_Validity_40_002 : 325|1@1+ (1,0) [0|1] ""  Central_ECU
 SG_ Loc_Validity_40_001 : 324|1@1+ (1,0) [0|1] ""  Central_ECU
 SG_ Loc_40_Blockcnt : 320|4@1+ (1,0) [0|15] ""  Central_ECU
 SG_ Loc_40_CRC : 296|16@1+ (1,0) [0|65535] ""  Central_ECU
 SG_ Loc_40_AliveCtr : 312|8@1+ (1,0) [0|255] ""  Central_ECU
 SG_ Loc_SNR_40_004 : 237|11@1+ (0.0625,0) [0|40] "dB"  Central_ECU
 SG_ Loc_SNR_40_003 : 163|11@1+ (0.0625,0) [0|40] "dB"  Central_ECU
 SG_ Loc_SNR_40_002 : 89|11@1+ (0.0625,0) [0|40] "dB"  Central_ECU
 SG_ Loc_RCS_40_004 : 286|10@1+ (0.125,-50) [-50|70] "dBm^2"  Central_ECU
 SG_ Loc_RCS_40_003 : 212|10@1+ (0.125,-50) [-50|70] "dBm^2"  Central_ECU
 SG_ Loc_RCS_40_002 : 138|10@1+ (0.125,-50) [-50|70] "dBm^2"  Central_ECU
 SG_ Loc_RadialVelo_40_004 : 248|15@1+ (0.0078125,-128) [-128|127] "m/s"  Central_ECU
 SG_ Loc_RadialVelo_40_003 : 174|15@1+ (0.0078125,-128) [-128|127] "m/s"  Central_ECU
 SG_ Loc_RadialVelo_40_002 : 100|15@1+ (0.0078125,-128) [-128|127] "m/s"  Central_ECU
 SG_ Loc_RadialDist_40_004 : 222|15@1+ (0.0078125,0) [0|250] "m"  Central_ECU
 SG_ Loc_RadialDist_40_003 : 148|15@1+ (0.0078125,0) [0|250] "m"  Central_ECU
 SG_ Loc_RadialDist_40_002 : 74|15@1+ (0.0078125,0) [0|250] "m"  Central_ECU
 SG_ Loc_ElevAngle_40_004 : 275|11@1+ (0.001,-0.785) [-0.785|0.785] "rad"  Central_ECU
 SG_ Loc_ElevAngle_40_003 : 201|11@1+ (0.001,-0.785) [-0.785|0.785] "rad"  Central_ECU
 SG_ Loc_ElevAngle_40_002 : 127|11@1+ (0.001,-0.785) [-0.785|0.785] "rad"  Central_ECU
 SG_ Loc_AziAngle_40_004 : 263|12@1+ (0.001,-1.57) [-1.57|1.57] "rad"  Central_ECU
 SG_ Loc_AziAngle_40_003 : 189|12@1+ (0.001,-1.57) [-1.57|1.57] "rad"  Central_ECU
 SG_ Loc_AziAngle_40_002 : 115|12@1+ (0.001,-1.57) [-1.57|1.57] "rad"  Central_ECU
 SG_ Loc_RCS_40_001 : 64|10@1+ (0.125,-50) [-50|70] "dBm^2"  Central_ECU
 SG_ Loc_ElevAngle_40_001 : 53|11@1+ (0.001,-0.785) [-0.785|0.785] "rad"  Central_ECU
 SG_ Loc_AziAngle_40_001 : 41|12@1+ (0.001,-1.57) [-1.57|1.57] "rad"  Central_ECU
 SG_ Loc_RadialVelo_40_001 : 26|15@1+ (0.0078125,-128) [-128|127] "m/s"  Central_ECU
 SG_ Loc_SNR_40_001 : 15|11@1+ (0.0625,0) [0|40] "dB"  Central_ECU
 SG_ Loc_RadialDist_40_001 : 0|15@1+ (0.0078125,0) [0|250] "m"  Central_ECU

BO_ 313 Location_Data_39: 64 Radar
 SG_ Loc_ElevAngleQly_39_004 : 416|8@1+ (1,0) [0|255] ""  Central_ECU
 SG_ Loc_ElevAngleQly_39_003 : 392|8@1+ (1,0) [0|255] ""  Central_ECU
 SG_ Loc_ElevAngleQly_39_002 : 368|8@1+ (1,0) [0|255] ""  Central_ECU
 SG_ Loc_ElevAngleQly_39_001 : 344|8@1+ (1,0) [0|255] ""  Central_ECU
 SG_ Loc_AziAngleQly_39_004 : 408|8@1+ (1,0) [0|255] ""  Central_ECU
 SG_ Loc_AziAngleQly_39_003 : 384|8@1+ (1,0) [0|255] ""  Central_ECU
 SG_ Loc_AziAngleQly_39_002 : 360|8@1+ (1,0) [0|255] ""  Central_ECU
 SG_ Loc_AziAngleQly_39_001 : 336|8@1+ (1,0) [0|255] ""  Central_ECU
 SG_ Loc_RadialDistVeloQly_39_004 : 400|8@1+ (1,0) [0|255] ""  Central_ECU
 SG_ Loc_RadialDistVeloQly_39_003 : 376|8@1+ (1,0) [0|255] ""  Central_ECU
 SG_ Loc_RadialDistVeloQly_39_002 : 352|8@1+ (1,0) [0|255] ""  Central_ECU
 SG_ Loc_RadialDistVeloQly_39_001 : 328|8@1+ (1,0) [0|255] ""  Central_ECU
 SG_ Loc_Validity_39_004 : 327|1@1+ (1,0) [0|1] ""  Central_ECU
 SG_ Loc_Validity_39_003 : 326|1@1+ (1,0) [0|1] ""  Central_ECU
 SG_ Loc_Validity_39_002 : 325|1@1+ (1,0) [0|1] ""  Central_ECU
 SG_ Loc_Validity_39_001 : 324|1@1+ (1,0) [0|1] ""  Central_ECU
 SG_ Loc_39_Blockcnt : 320|4@1+ (1,0) [0|15] ""  Central_ECU
 SG_ Loc_39_CRC : 296|16@1+ (1,0) [0|65535] ""  Central_ECU
 SG_ Loc_39_AliveCtr : 312|8@1+ (1,0) [0|255] ""  Central_ECU
 SG_ Loc_SNR_39_004 : 237|11@1+ (0.0625,0) [0|40] "dB"  Central_ECU
 SG_ Loc_SNR_39_003 : 163|11@1+ (0.0625,0) [0|40] "dB"  Central_ECU
 SG_ Loc_SNR_39_002 : 89|11@1+ (0.0625,0) [0|40] "dB"  Central_ECU
 SG_ Loc_RCS_39_004 : 286|10@1+ (0.125,-50) [-50|70] "dBm^2"  Central_ECU
 SG_ Loc_RCS_39_003 : 212|10@1+ (0.125,-50) [-50|70] "dBm^2"  Central_ECU
 SG_ Loc_RCS_39_002 : 138|10@1+ (0.125,-50) [-50|70] "dBm^2"  Central_ECU
 SG_ Loc_RadialVelo_39_004 : 248|15@1+ (0.0078125,-128) [-128|127] "m/s"  Central_ECU
 SG_ Loc_RadialVelo_39_003 : 174|15@1+ (0.0078125,-128) [-128|127] "m/s"  Central_ECU
 SG_ Loc_RadialVelo_39_002 : 100|15@1+ (0.0078125,-128) [-128|127] "m/s"  Central_ECU
 SG_ Loc_RadialDist_39_004 : 222|15@1+ (0.0078125,0) [0|250] "m"  Central_ECU
 SG_ Loc_RadialDist_39_003 : 148|15@1+ (0.0078125,0) [0|250] "m"  Central_ECU
 SG_ Loc_RadialDist_39_002 : 74|15@1+ (0.0078125,0) [0|250] "m"  Central_ECU
 SG_ Loc_ElevAngle_39_004 : 275|11@1+ (0.001,-0.785) [-0.785|0.785] "rad"  Central_ECU
 SG_ Loc_ElevAngle_39_003 : 201|11@1+ (0.001,-0.785) [-0.785|0.785] "rad"  Central_ECU
 SG_ Loc_ElevAngle_39_002 : 127|11@1+ (0.001,-0.785) [-0.785|0.785] "rad"  Central_ECU
 SG_ Loc_AziAngle_39_004 : 263|12@1+ (0.001,-1.57) [-1.57|1.57] "rad"  Central_ECU
 SG_ Loc_AziAngle_39_003 : 189|12@1+ (0.001,-1.57) [-1.57|1.57] "rad"  Central_ECU
 SG_ Loc_AziAngle_39_002 : 115|12@1+ (0.001,-1.57) [-1.57|1.57] "rad"  Central_ECU
 SG_ Loc_RCS_39_001 : 64|10@1+ (0.125,-50) [-50|70] "dBm^2"  Central_ECU
 SG_ Loc_ElevAngle_39_001 : 53|11@1+ (0.001,-0.785) [-0.785|0.785] "rad"  Central_ECU
 SG_ Loc_AziAngle_39_001 : 41|12@1+ (0.001,-1.57) [-1.57|1.57] "rad"  Central_ECU
 SG_ Loc_RadialVelo_39_001 : 26|15@1+ (0.0078125,-128) [-128|127] "m/s"  Central_ECU
 SG_ Loc_SNR_39_001 : 15|11@1+ (0.0625,0) [0|40] "dB"  Central_ECU
 SG_ Loc_RadialDist_39_001 : 0|15@1+ (0.0078125,0) [0|250] "m"  Central_ECU

BO_ 312 Location_Data_38: 64 Radar
 SG_ Loc_ElevAngleQly_38_004 : 416|8@1+ (1,0) [0|255] ""  Central_ECU
 SG_ Loc_ElevAngleQly_38_003 : 392|8@1+ (1,0) [0|255] ""  Central_ECU
 SG_ Loc_ElevAngleQly_38_002 : 368|8@1+ (1,0) [0|255] ""  Central_ECU
 SG_ Loc_ElevAngleQly_38_001 : 344|8@1+ (1,0) [0|255] ""  Central_ECU
 SG_ Loc_AziAngleQly_38_004 : 408|8@1+ (1,0) [0|255] ""  Central_ECU
 SG_ Loc_AziAngleQly_38_003 : 384|8@1+ (1,0) [0|255] ""  Central_ECU
 SG_ Loc_AziAngleQly_38_002 : 360|8@1+ (1,0) [0|255] ""  Central_ECU
 SG_ Loc_AziAngleQly_38_001 : 336|8@1+ (1,0) [0|255] ""  Central_ECU
 SG_ Loc_RadialDistVeloQly_38_004 : 400|8@1+ (1,0) [0|255] ""  Central_ECU
 SG_ Loc_RadialDistVeloQly_38_003 : 376|8@1+ (1,0) [0|255] ""  Central_ECU
 SG_ Loc_RadialDistVeloQly_38_002 : 352|8@1+ (1,0) [0|255] ""  Central_ECU
 SG_ Loc_RadialDistVeloQly_38_001 : 328|8@1+ (1,0) [0|255] ""  Central_ECU
 SG_ Loc_Validity_38_004 : 327|1@1+ (1,0) [0|1] ""  Central_ECU
 SG_ Loc_Validity_38_003 : 326|1@1+ (1,0) [0|1] ""  Central_ECU
 SG_ Loc_Validity_38_002 : 325|1@1+ (1,0) [0|1] ""  Central_ECU
 SG_ Loc_Validity_38_001 : 324|1@1+ (1,0) [0|1] ""  Central_ECU
 SG_ Loc_38_Blockcnt : 320|4@1+ (1,0) [0|15] ""  Central_ECU
 SG_ Loc_38_CRC : 296|16@1+ (1,0) [0|65535] ""  Central_ECU
 SG_ Loc_38_AliveCtr : 312|8@1+ (1,0) [0|255] ""  Central_ECU
 SG_ Loc_SNR_38_004 : 237|11@1+ (0.0625,0) [0|40] "dB"  Central_ECU
 SG_ Loc_SNR_38_003 : 163|11@1+ (0.0625,0) [0|40] "dB"  Central_ECU
 SG_ Loc_SNR_38_002 : 89|11@1+ (0.0625,0) [0|40] "dB"  Central_ECU
 SG_ Loc_RCS_38_004 : 286|10@1+ (0.125,-50) [-50|70] "dBm^2"  Central_ECU
 SG_ Loc_RCS_38_003 : 212|10@1+ (0.125,-50) [-50|70] "dBm^2"  Central_ECU
 SG_ Loc_RCS_38_002 : 138|10@1+ (0.125,-50) [-50|70] "dBm^2"  Central_ECU
 SG_ Loc_RadialVelo_38_004 : 248|15@1+ (0.0078125,-128) [-128|127] "m/s"  Central_ECU
 SG_ Loc_RadialVelo_38_003 : 174|15@1+ (0.0078125,-128) [-128|127] "m/s"  Central_ECU
 SG_ Loc_RadialVelo_38_002 : 100|15@1+ (0.0078125,-128) [-128|127] "m/s"  Central_ECU
 SG_ Loc_RadialDist_38_004 : 222|15@1+ (0.0078125,0) [0|250] "m"  Central_ECU
 SG_ Loc_RadialDist_38_003 : 148|15@1+ (0.0078125,0) [0|250] "m"  Central_ECU
 SG_ Loc_RadialDist_38_002 : 74|15@1+ (0.0078125,0) [0|250] "m"  Central_ECU
 SG_ Loc_ElevAngle_38_004 : 275|11@1+ (0.001,-0.785) [-0.785|0.785] "rad"  Central_ECU
 SG_ Loc_ElevAngle_38_003 : 201|11@1+ (0.001,-0.785) [-0.785|0.785] "rad"  Central_ECU
 SG_ Loc_ElevAngle_38_002 : 127|11@1+ (0.001,-0.785) [-0.785|0.785] "rad"  Central_ECU
 SG_ Loc_AziAngle_38_004 : 263|12@1+ (0.001,-1.57) [-1.57|1.57] "rad"  Central_ECU
 SG_ Loc_AziAngle_38_003 : 189|12@1+ (0.001,-1.57) [-1.57|1.57] "rad"  Central_ECU
 SG_ Loc_AziAngle_38_002 : 115|12@1+ (0.001,-1.57) [-1.57|1.57] "rad"  Central_ECU
 SG_ Loc_RCS_38_001 : 64|10@1+ (0.125,-50) [-50|70] "dBm^2"  Central_ECU
 SG_ Loc_ElevAngle_38_001 : 53|11@1+ (0.001,-0.785) [-0.785|0.785] "rad"  Central_ECU
 SG_ Loc_AziAngle_38_001 : 41|12@1+ (0.001,-1.57) [-1.57|1.57] "rad"  Central_ECU
 SG_ Loc_RadialVelo_38_001 : 26|15@1+ (0.0078125,-128) [-128|127] "m/s"  Central_ECU
 SG_ Loc_SNR_38_001 : 15|11@1+ (0.0625,0) [0|40] "dB"  Central_ECU
 SG_ Loc_RadialDist_38_001 : 0|15@1+ (0.0078125,0) [0|250] "m"  Central_ECU

BO_ 311 Location_Data_37: 64 Radar
 SG_ Loc_ElevAngleQly_37_004 : 416|8@1+ (1,0) [0|255] ""  Central_ECU
 SG_ Loc_ElevAngleQly_37_003 : 392|8@1+ (1,0) [0|255] ""  Central_ECU
 SG_ Loc_ElevAngleQly_37_002 : 368|8@1+ (1,0) [0|255] ""  Central_ECU
 SG_ Loc_ElevAngleQly_37_001 : 344|8@1+ (1,0) [0|255] ""  Central_ECU
 SG_ Loc_AziAngleQly_37_004 : 408|8@1+ (1,0) [0|255] ""  Central_ECU
 SG_ Loc_AziAngleQly_37_003 : 384|8@1+ (1,0) [0|255] ""  Central_ECU
 SG_ Loc_AziAngleQly_37_002 : 360|8@1+ (1,0) [0|255] ""  Central_ECU
 SG_ Loc_AziAngleQly_37_001 : 336|8@1+ (1,0) [0|255] ""  Central_ECU
 SG_ Loc_RadialDistVeloQly_37_004 : 400|8@1+ (1,0) [0|255] ""  Central_ECU
 SG_ Loc_RadialDistVeloQly_37_003 : 376|8@1+ (1,0) [0|255] ""  Central_ECU
 SG_ Loc_RadialDistVeloQly_37_002 : 352|8@1+ (1,0) [0|255] ""  Central_ECU
 SG_ Loc_RadialDistVeloQly_37_001 : 328|8@1+ (1,0) [0|255] ""  Central_ECU
 SG_ Loc_Validity_37_004 : 327|1@1+ (1,0) [0|1] ""  Central_ECU
 SG_ Loc_Validity_37_003 : 326|1@1+ (1,0) [0|1] ""  Central_ECU
 SG_ Loc_Validity_37_002 : 325|1@1+ (1,0) [0|1] ""  Central_ECU
 SG_ Loc_Validity_37_001 : 324|1@1+ (1,0) [0|1] ""  Central_ECU
 SG_ Loc_37_Blockcnt : 320|4@1+ (1,0) [0|15] ""  Central_ECU
 SG_ Loc_37_CRC : 296|16@1+ (1,0) [0|65535] ""  Central_ECU
 SG_ Loc_37_AliveCtr : 312|8@1+ (1,0) [0|255] ""  Central_ECU
 SG_ Loc_SNR_37_004 : 237|11@1+ (0.0625,0) [0|40] "dB"  Central_ECU
 SG_ Loc_SNR_37_003 : 163|11@1+ (0.0625,0) [0|40] "dB"  Central_ECU
 SG_ Loc_SNR_37_002 : 89|11@1+ (0.0625,0) [0|40] "dB"  Central_ECU
 SG_ Loc_RCS_37_004 : 286|10@1+ (0.125,-50) [-50|70] "dBm^2"  Central_ECU
 SG_ Loc_RCS_37_003 : 212|10@1+ (0.125,-50) [-50|70] "dBm^2"  Central_ECU
 SG_ Loc_RCS_37_002 : 138|10@1+ (0.125,-50) [-50|70] "dBm^2"  Central_ECU
 SG_ Loc_RadialVelo_37_004 : 248|15@1+ (0.0078125,-128) [-128|127] "m/s"  Central_ECU
 SG_ Loc_RadialVelo_37_003 : 174|15@1+ (0.0078125,-128) [-128|127] "m/s"  Central_ECU
 SG_ Loc_RadialVelo_37_002 : 100|15@1+ (0.0078125,-128) [-128|127] "m/s"  Central_ECU
 SG_ Loc_RadialDist_37_004 : 222|15@1+ (0.0078125,0) [0|250] "m"  Central_ECU
 SG_ Loc_RadialDist_37_003 : 148|15@1+ (0.0078125,0) [0|250] "m"  Central_ECU
 SG_ Loc_RadialDist_37_002 : 74|15@1+ (0.0078125,0) [0|250] "m"  Central_ECU
 SG_ Loc_ElevAngle_37_004 : 275|11@1+ (0.001,-0.785) [-0.785|0.785] "rad"  Central_ECU
 SG_ Loc_ElevAngle_37_003 : 201|11@1+ (0.001,-0.785) [-0.785|0.785] "rad"  Central_ECU
 SG_ Loc_ElevAngle_37_002 : 127|11@1+ (0.001,-0.785) [-0.785|0.785] "rad"  Central_ECU
 SG_ Loc_AziAngle_37_004 : 263|12@1+ (0.001,-1.57) [-1.57|1.57] "rad"  Central_ECU
 SG_ Loc_AziAngle_37_003 : 189|12@1+ (0.001,-1.57) [-1.57|1.57] "rad"  Central_ECU
 SG_ Loc_AziAngle_37_002 : 115|12@1+ (0.001,-1.57) [-1.57|1.57] "rad"  Central_ECU
 SG_ Loc_RCS_37_001 : 64|10@1+ (0.125,-50) [-50|70] "dBm^2"  Central_ECU
 SG_ Loc_ElevAngle_37_001 : 53|11@1+ (0.001,-0.785) [-0.785|0.785] "rad"  Central_ECU
 SG_ Loc_AziAngle_37_001 : 41|12@1+ (0.001,-1.57) [-1.57|1.57] "rad"  Central_ECU
 SG_ Loc_RadialVelo_37_001 : 26|15@1+ (0.0078125,-128) [-128|127] "m/s"  Central_ECU
 SG_ Loc_SNR_37_001 : 15|11@1+ (0.0625,0) [0|40] "dB"  Central_ECU
 SG_ Loc_RadialDist_37_001 : 0|15@1+ (0.0078125,0) [0|250] "m"  Central_ECU

BO_ 310 Location_Data_36: 64 Radar
 SG_ Loc_ElevAngleQly_36_004 : 416|8@1+ (1,0) [0|255] ""  Central_ECU
 SG_ Loc_ElevAngleQly_36_003 : 392|8@1+ (1,0) [0|255] ""  Central_ECU
 SG_ Loc_ElevAngleQly_36_002 : 368|8@1+ (1,0) [0|255] ""  Central_ECU
 SG_ Loc_ElevAngleQly_36_001 : 344|8@1+ (1,0) [0|255] ""  Central_ECU
 SG_ Loc_AziAngleQly_36_004 : 408|8@1+ (1,0) [0|255] ""  Central_ECU
 SG_ Loc_AziAngleQly_36_003 : 384|8@1+ (1,0) [0|255] ""  Central_ECU
 SG_ Loc_AziAngleQly_36_002 : 360|8@1+ (1,0) [0|255] ""  Central_ECU
 SG_ Loc_AziAngleQly_36_001 : 336|8@1+ (1,0) [0|255] ""  Central_ECU
 SG_ Loc_RadialDistVeloQly_36_004 : 400|8@1+ (1,0) [0|255] ""  Central_ECU
 SG_ Loc_RadialDistVeloQly_36_003 : 376|8@1+ (1,0) [0|255] ""  Central_ECU
 SG_ Loc_RadialDistVeloQly_36_002 : 352|8@1+ (1,0) [0|255] ""  Central_ECU
 SG_ Loc_RadialDistVeloQly_36_001 : 328|8@1+ (1,0) [0|255] ""  Central_ECU
 SG_ Loc_Validity_36_004 : 327|1@1+ (1,0) [0|1] ""  Central_ECU
 SG_ Loc_Validity_36_003 : 326|1@1+ (1,0) [0|1] ""  Central_ECU
 SG_ Loc_Validity_36_002 : 325|1@1+ (1,0) [0|1] ""  Central_ECU
 SG_ Loc_Validity_36_001 : 324|1@1+ (1,0) [0|1] ""  Central_ECU
 SG_ Loc_36_Blockcnt : 320|4@1+ (1,0) [0|15] ""  Central_ECU
 SG_ Loc_36_CRC : 296|16@1+ (1,0) [0|65535] ""  Central_ECU
 SG_ Loc_36_AliveCtr : 312|8@1+ (1,0) [0|255] ""  Central_ECU
 SG_ Loc_SNR_36_004 : 237|11@1+ (0.0625,0) [0|40] "dB"  Central_ECU
 SG_ Loc_SNR_36_003 : 163|11@1+ (0.0625,0) [0|40] "dB"  Central_ECU
 SG_ Loc_SNR_36_002 : 89|11@1+ (0.0625,0) [0|40] "dB"  Central_ECU
 SG_ Loc_RCS_36_004 : 286|10@1+ (0.125,-50) [-50|70] "dBm^2"  Central_ECU
 SG_ Loc_RCS_36_003 : 212|10@1+ (0.125,-50) [-50|70] "dBm^2"  Central_ECU
 SG_ Loc_RCS_36_002 : 138|10@1+ (0.125,-50) [-50|70] "dBm^2"  Central_ECU
 SG_ Loc_RadialVelo_36_004 : 248|15@1+ (0.0078125,-128) [-128|127] "m/s"  Central_ECU
 SG_ Loc_RadialVelo_36_003 : 174|15@1+ (0.0078125,-128) [-128|127] "m/s"  Central_ECU
 SG_ Loc_RadialVelo_36_002 : 100|15@1+ (0.0078125,-128) [-128|127] "m/s"  Central_ECU
 SG_ Loc_RadialDist_36_004 : 222|15@1+ (0.0078125,0) [0|250] "m"  Central_ECU
 SG_ Loc_RadialDist_36_003 : 148|15@1+ (0.0078125,0) [0|250] "m"  Central_ECU
 SG_ Loc_RadialDist_36_002 : 74|15@1+ (0.0078125,0) [0|250] "m"  Central_ECU
 SG_ Loc_ElevAngle_36_004 : 275|11@1+ (0.001,-0.785) [-0.785|0.785] "rad"  Central_ECU
 SG_ Loc_ElevAngle_36_003 : 201|11@1+ (0.001,-0.785) [-0.785|0.785] "rad"  Central_ECU
 SG_ Loc_ElevAngle_36_002 : 127|11@1+ (0.001,-0.785) [-0.785|0.785] "rad"  Central_ECU
 SG_ Loc_AziAngle_36_004 : 263|12@1+ (0.001,-1.57) [-1.57|1.57] "rad"  Central_ECU
 SG_ Loc_AziAngle_36_003 : 189|12@1+ (0.001,-1.57) [-1.57|1.57] "rad"  Central_ECU
 SG_ Loc_AziAngle_36_002 : 115|12@1+ (0.001,-1.57) [-1.57|1.57] "rad"  Central_ECU
 SG_ Loc_RCS_36_001 : 64|10@1+ (0.125,-50) [-50|70] "dBm^2"  Central_ECU
 SG_ Loc_ElevAngle_36_001 : 53|11@1+ (0.001,-0.785) [-0.785|0.785] "rad"  Central_ECU
 SG_ Loc_AziAngle_36_001 : 41|12@1+ (0.001,-1.57) [-1.57|1.57] "rad"  Central_ECU
 SG_ Loc_RadialVelo_36_001 : 26|15@1+ (0.0078125,-128) [-128|127] "m/s"  Central_ECU
 SG_ Loc_SNR_36_001 : 15|11@1+ (0.0625,0) [0|40] "dB"  Central_ECU
 SG_ Loc_RadialDist_36_001 : 0|15@1+ (0.0078125,0) [0|250] "m"  Central_ECU

BO_ 309 Location_Data_35: 64 Radar
 SG_ Loc_ElevAngleQly_35_004 : 416|8@1+ (1,0) [0|255] ""  Central_ECU
 SG_ Loc_ElevAngleQly_35_003 : 392|8@1+ (1,0) [0|255] ""  Central_ECU
 SG_ Loc_ElevAngleQly_35_002 : 368|8@1+ (1,0) [0|255] ""  Central_ECU
 SG_ Loc_ElevAngleQly_35_001 : 344|8@1+ (1,0) [0|255] ""  Central_ECU
 SG_ Loc_AziAngleQly_35_004 : 408|8@1+ (1,0) [0|255] ""  Central_ECU
 SG_ Loc_AziAngleQly_35_003 : 384|8@1+ (1,0) [0|255] ""  Central_ECU
 SG_ Loc_AziAngleQly_35_002 : 360|8@1+ (1,0) [0|255] ""  Central_ECU
 SG_ Loc_AziAngleQly_35_001 : 336|8@1+ (1,0) [0|255] ""  Central_ECU
 SG_ Loc_RadialDistVeloQly_35_004 : 400|8@1+ (1,0) [0|255] ""  Central_ECU
 SG_ Loc_RadialDistVeloQly_35_003 : 376|8@1+ (1,0) [0|255] ""  Central_ECU
 SG_ Loc_RadialDistVeloQly_35_002 : 352|8@1+ (1,0) [0|255] ""  Central_ECU
 SG_ Loc_RadialDistVeloQly_35_001 : 328|8@1+ (1,0) [0|255] ""  Central_ECU
 SG_ Loc_Validity_35_004 : 327|1@1+ (1,0) [0|1] ""  Central_ECU
 SG_ Loc_Validity_35_003 : 326|1@1+ (1,0) [0|1] ""  Central_ECU
 SG_ Loc_Validity_35_002 : 325|1@1+ (1,0) [0|1] ""  Central_ECU
 SG_ Loc_Validity_35_001 : 324|1@1+ (1,0) [0|1] ""  Central_ECU
 SG_ Loc_35_Blockcnt : 320|4@1+ (1,0) [0|15] ""  Central_ECU
 SG_ Loc_35_CRC : 296|16@1+ (1,0) [0|65535] ""  Central_ECU
 SG_ Loc_35_AliveCtr : 312|8@1+ (1,0) [0|255] ""  Central_ECU
 SG_ Loc_SNR_35_004 : 237|11@1+ (0.0625,0) [0|40] "dB"  Central_ECU
 SG_ Loc_SNR_35_003 : 163|11@1+ (0.0625,0) [0|40] "dB"  Central_ECU
 SG_ Loc_SNR_35_002 : 89|11@1+ (0.0625,0) [0|40] "dB"  Central_ECU
 SG_ Loc_RCS_35_004 : 286|10@1+ (0.125,-50) [-50|70] "dBm^2"  Central_ECU
 SG_ Loc_RCS_35_003 : 212|10@1+ (0.125,-50) [-50|70] "dBm^2"  Central_ECU
 SG_ Loc_RCS_35_002 : 138|10@1+ (0.125,-50) [-50|70] "dBm^2"  Central_ECU
 SG_ Loc_RadialVelo_35_004 : 248|15@1+ (0.0078125,-128) [-128|127] "m/s"  Central_ECU
 SG_ Loc_RadialVelo_35_003 : 174|15@1+ (0.0078125,-128) [-128|127] "m/s"  Central_ECU
 SG_ Loc_RadialVelo_35_002 : 100|15@1+ (0.0078125,-128) [-128|127] "m/s"  Central_ECU
 SG_ Loc_RadialDist_35_004 : 222|15@1+ (0.0078125,0) [0|250] "m"  Central_ECU
 SG_ Loc_RadialDist_35_003 : 148|15@1+ (0.0078125,0) [0|250] "m"  Central_ECU
 SG_ Loc_RadialDist_35_002 : 74|15@1+ (0.0078125,0) [0|250] "m"  Central_ECU
 SG_ Loc_ElevAngle_35_004 : 275|11@1+ (0.001,-0.785) [-0.785|0.785] "rad"  Central_ECU
 SG_ Loc_ElevAngle_35_003 : 201|11@1+ (0.001,-0.785) [-0.785|0.785] "rad"  Central_ECU
 SG_ Loc_ElevAngle_35_002 : 127|11@1+ (0.001,-0.785) [-0.785|0.785] "rad"  Central_ECU
 SG_ Loc_AziAngle_35_004 : 263|12@1+ (0.001,-1.57) [-1.57|1.57] "rad"  Central_ECU
 SG_ Loc_AziAngle_35_003 : 189|12@1+ (0.001,-1.57) [-1.57|1.57] "rad"  Central_ECU
 SG_ Loc_AziAngle_35_002 : 115|12@1+ (0.001,-1.57) [-1.57|1.57] "rad"  Central_ECU
 SG_ Loc_RCS_35_001 : 64|10@1+ (0.125,-50) [-50|70] "dBm^2"  Central_ECU
 SG_ Loc_ElevAngle_35_001 : 53|11@1+ (0.001,-0.785) [-0.785|0.785] "rad"  Central_ECU
 SG_ Loc_AziAngle_35_001 : 41|12@1+ (0.001,-1.57) [-1.57|1.57] "rad"  Central_ECU
 SG_ Loc_RadialVelo_35_001 : 26|15@1+ (0.0078125,-128) [-128|127] "m/s"  Central_ECU
 SG_ Loc_SNR_35_001 : 15|11@1+ (0.0625,0) [0|40] "dB"  Central_ECU
 SG_ Loc_RadialDist_35_001 : 0|15@1+ (0.0078125,0) [0|250] "m"  Central_ECU

BO_ 308 Location_Data_34: 64 Radar
 SG_ Loc_ElevAngleQly_34_004 : 416|8@1+ (1,0) [0|255] ""  Central_ECU
 SG_ Loc_ElevAngleQly_34_003 : 392|8@1+ (1,0) [0|255] ""  Central_ECU
 SG_ Loc_ElevAngleQly_34_002 : 368|8@1+ (1,0) [0|255] ""  Central_ECU
 SG_ Loc_ElevAngleQly_34_001 : 344|8@1+ (1,0) [0|255] ""  Central_ECU
 SG_ Loc_AziAngleQly_34_004 : 408|8@1+ (1,0) [0|255] ""  Central_ECU
 SG_ Loc_AziAngleQly_34_003 : 384|8@1+ (1,0) [0|255] ""  Central_ECU
 SG_ Loc_AziAngleQly_34_002 : 360|8@1+ (1,0) [0|255] ""  Central_ECU
 SG_ Loc_AziAngleQly_34_001 : 336|8@1+ (1,0) [0|255] ""  Central_ECU
 SG_ Loc_RadialDistVeloQly_34_004 : 400|8@1+ (1,0) [0|255] ""  Central_ECU
 SG_ Loc_RadialDistVeloQly_34_003 : 376|8@1+ (1,0) [0|255] ""  Central_ECU
 SG_ Loc_RadialDistVeloQly_34_002 : 352|8@1+ (1,0) [0|255] ""  Central_ECU
 SG_ Loc_RadialDistVeloQly_34_001 : 328|8@1+ (1,0) [0|255] ""  Central_ECU
 SG_ Loc_Validity_34_004 : 327|1@1+ (1,0) [0|1] ""  Central_ECU
 SG_ Loc_Validity_34_003 : 326|1@1+ (1,0) [0|1] ""  Central_ECU
 SG_ Loc_Validity_34_002 : 325|1@1+ (1,0) [0|1] ""  Central_ECU
 SG_ Loc_Validity_34_001 : 324|1@1+ (1,0) [0|1] ""  Central_ECU
 SG_ Loc_34_Blockcnt : 320|4@1+ (1,0) [0|15] ""  Central_ECU
 SG_ Loc_34_CRC : 296|16@1+ (1,0) [0|65535] ""  Central_ECU
 SG_ Loc_34_AliveCtr : 312|8@1+ (1,0) [0|255] ""  Central_ECU
 SG_ Loc_SNR_34_004 : 237|11@1+ (0.0625,0) [0|40] "dB"  Central_ECU
 SG_ Loc_SNR_34_003 : 163|11@1+ (0.0625,0) [0|40] "dB"  Central_ECU
 SG_ Loc_SNR_34_002 : 89|11@1+ (0.0625,0) [0|40] "dB"  Central_ECU
 SG_ Loc_RCS_34_004 : 286|10@1+ (0.125,-50) [-50|70] "dBm^2"  Central_ECU
 SG_ Loc_RCS_34_003 : 212|10@1+ (0.125,-50) [-50|70] "dBm^2"  Central_ECU
 SG_ Loc_RCS_34_002 : 138|10@1+ (0.125,-50) [-50|70] "dBm^2"  Central_ECU
 SG_ Loc_RadialVelo_34_004 : 248|15@1+ (0.0078125,-128) [-128|127] "m/s"  Central_ECU
 SG_ Loc_RadialVelo_34_003 : 174|15@1+ (0.0078125,-128) [-128|127] "m/s"  Central_ECU
 SG_ Loc_RadialVelo_34_002 : 100|15@1+ (0.0078125,-128) [-128|127] "m/s"  Central_ECU
 SG_ Loc_RadialDist_34_004 : 222|15@1+ (0.0078125,0) [0|250] "m"  Central_ECU
 SG_ Loc_RadialDist_34_003 : 148|15@1+ (0.0078125,0) [0|250] "m"  Central_ECU
 SG_ Loc_RadialDist_34_002 : 74|15@1+ (0.0078125,0) [0|250] "m"  Central_ECU
 SG_ Loc_ElevAngle_34_004 : 275|11@1+ (0.001,-0.785) [-0.785|0.785] "rad"  Central_ECU
 SG_ Loc_ElevAngle_34_003 : 201|11@1+ (0.001,-0.785) [-0.785|0.785] "rad"  Central_ECU
 SG_ Loc_ElevAngle_34_002 : 127|11@1+ (0.001,-0.785) [-0.785|0.785] "rad"  Central_ECU
 SG_ Loc_AziAngle_34_004 : 263|12@1+ (0.001,-1.57) [-1.57|1.57] "rad"  Central_ECU
 SG_ Loc_AziAngle_34_003 : 189|12@1+ (0.001,-1.57) [-1.57|1.57] "rad"  Central_ECU
 SG_ Loc_AziAngle_34_002 : 115|12@1+ (0.001,-1.57) [-1.57|1.57] "rad"  Central_ECU
 SG_ Loc_RCS_34_001 : 64|10@1+ (0.125,-50) [-50|70] "dBm^2"  Central_ECU
 SG_ Loc_ElevAngle_34_001 : 53|11@1+ (0.001,-0.785) [-0.785|0.785] "rad"  Central_ECU
 SG_ Loc_AziAngle_34_001 : 41|12@1+ (0.001,-1.57) [-1.57|1.57] "rad"  Central_ECU
 SG_ Loc_RadialVelo_34_001 : 26|15@1+ (0.0078125,-128) [-128|127] "m/s"  Central_ECU
 SG_ Loc_SNR_34_001 : 15|11@1+ (0.0625,0) [0|40] "dB"  Central_ECU
 SG_ Loc_RadialDist_34_001 : 0|15@1+ (0.0078125,0) [0|250] "m"  Central_ECU

BO_ 307 Location_Data_33: 64 Radar
 SG_ Loc_ElevAngleQly_33_004 : 416|8@1+ (1,0) [0|255] ""  Central_ECU
 SG_ Loc_ElevAngleQly_33_003 : 392|8@1+ (1,0) [0|255] ""  Central_ECU
 SG_ Loc_ElevAngleQly_33_002 : 368|8@1+ (1,0) [0|255] ""  Central_ECU
 SG_ Loc_ElevAngleQly_33_001 : 344|8@1+ (1,0) [0|255] ""  Central_ECU
 SG_ Loc_AziAngleQly_33_004 : 408|8@1+ (1,0) [0|255] ""  Central_ECU
 SG_ Loc_AziAngleQly_33_003 : 384|8@1+ (1,0) [0|255] ""  Central_ECU
 SG_ Loc_AziAngleQly_33_002 : 360|8@1+ (1,0) [0|255] ""  Central_ECU
 SG_ Loc_AziAngleQly_33_001 : 336|8@1+ (1,0) [0|255] ""  Central_ECU
 SG_ Loc_RadialDistVeloQly_33_004 : 400|8@1+ (1,0) [0|255] ""  Central_ECU
 SG_ Loc_RadialDistVeloQly_33_003 : 376|8@1+ (1,0) [0|255] ""  Central_ECU
 SG_ Loc_RadialDistVeloQly_33_002 : 352|8@1+ (1,0) [0|255] ""  Central_ECU
 SG_ Loc_RadialDistVeloQly_33_001 : 328|8@1+ (1,0) [0|255] ""  Central_ECU
 SG_ Loc_Validity_33_004 : 327|1@1+ (1,0) [0|1] ""  Central_ECU
 SG_ Loc_Validity_33_003 : 326|1@1+ (1,0) [0|1] ""  Central_ECU
 SG_ Loc_Validity_33_002 : 325|1@1+ (1,0) [0|1] ""  Central_ECU
 SG_ Loc_Validity_33_001 : 324|1@1+ (1,0) [0|1] ""  Central_ECU
 SG_ Loc_33_Blockcnt : 320|4@1+ (1,0) [0|15] ""  Central_ECU
 SG_ Loc_33_CRC : 296|16@1+ (1,0) [0|65535] ""  Central_ECU
 SG_ Loc_33_AliveCtr : 312|8@1+ (1,0) [0|255] ""  Central_ECU
 SG_ Loc_SNR_33_004 : 237|11@1+ (0.0625,0) [0|40] "dB"  Central_ECU
 SG_ Loc_SNR_33_003 : 163|11@1+ (0.0625,0) [0|40] "dB"  Central_ECU
 SG_ Loc_SNR_33_002 : 89|11@1+ (0.0625,0) [0|40] "dB"  Central_ECU
 SG_ Loc_RCS_33_004 : 286|10@1+ (0.125,-50) [-50|70] "dBm^2"  Central_ECU
 SG_ Loc_RCS_33_003 : 212|10@1+ (0.125,-50) [-50|70] "dBm^2"  Central_ECU
 SG_ Loc_RCS_33_002 : 138|10@1+ (0.125,-50) [-50|70] "dBm^2"  Central_ECU
 SG_ Loc_RadialVelo_33_004 : 248|15@1+ (0.0078125,-128) [-128|127] "m/s"  Central_ECU
 SG_ Loc_RadialVelo_33_003 : 174|15@1+ (0.0078125,-128) [-128|127] "m/s"  Central_ECU
 SG_ Loc_RadialVelo_33_002 : 100|15@1+ (0.0078125,-128) [-128|127] "m/s"  Central_ECU
 SG_ Loc_RadialDist_33_004 : 222|15@1+ (0.0078125,0) [0|250] "m"  Central_ECU
 SG_ Loc_RadialDist_33_003 : 148|15@1+ (0.0078125,0) [0|250] "m"  Central_ECU
 SG_ Loc_RadialDist_33_002 : 74|15@1+ (0.0078125,0) [0|250] "m"  Central_ECU
 SG_ Loc_ElevAngle_33_004 : 275|11@1+ (0.001,-0.785) [-0.785|0.785] "rad"  Central_ECU
 SG_ Loc_ElevAngle_33_003 : 201|11@1+ (0.001,-0.785) [-0.785|0.785] "rad"  Central_ECU
 SG_ Loc_ElevAngle_33_002 : 127|11@1+ (0.001,-0.785) [-0.785|0.785] "rad"  Central_ECU
 SG_ Loc_AziAngle_33_004 : 263|12@1+ (0.001,-1.57) [-1.57|1.57] "rad"  Central_ECU
 SG_ Loc_AziAngle_33_003 : 189|12@1+ (0.001,-1.57) [-1.57|1.57] "rad"  Central_ECU
 SG_ Loc_AziAngle_33_002 : 115|12@1+ (0.001,-1.57) [-1.57|1.57] "rad"  Central_ECU
 SG_ Loc_RCS_33_001 : 64|10@1+ (0.125,-50) [-50|70] "dBm^2"  Central_ECU
 SG_ Loc_ElevAngle_33_001 : 53|11@1+ (0.001,-0.785) [-0.785|0.785] "rad"  Central_ECU
 SG_ Loc_AziAngle_33_001 : 41|12@1+ (0.001,-1.57) [-1.57|1.57] "rad"  Central_ECU
 SG_ Loc_RadialVelo_33_001 : 26|15@1+ (0.0078125,-128) [-128|127] "m/s"  Central_ECU
 SG_ Loc_SNR_33_001 : 15|11@1+ (0.0625,0) [0|40] "dB"  Central_ECU
 SG_ Loc_RadialDist_33_001 : 0|15@1+ (0.0078125,0) [0|250] "m"  Central_ECU

CM_ SG_ 1969 Diag_Response_Dummy "Signal length is not a constant and it depends on the DIAG request/response with the range of  8 - 64 bits";
CM_ SG_ 1841 Diag_Request_Phys_Dummy "Signal length is not a constant and it depends on the DIAG request/response with the range of  8 - 64 bits";
CM_ SG_ 2015 Diag_Request_Func_Dummy "Signal length is not a constant and it depends on the DIAG request/response with the range of  8 - 64 bits";
CM_ SG_ 357 Radar_Error_Status "0: No Failure
1: Radar HW failure
2: Reserved";
CM_ SG_ 256 LocHeader_TimestampStatus "Autosar StbM_TimeBaseStatusType bitfield with extension:
Bit 0: TIMEOUT
Bit 1: Reserved1
Bit 2: SYNC_TO_GATEWAY
Bit 3: GLOBAL_TIME_BASE
Bit 4: TIMELEAP_FUTURE
Bit 5: TIMELEAP_PAST
Bit 6: Reserved6
Bit 7: Extension: GENERAL_ERROR";
BA_DEF_ BO_  "CANFD_BRS" ENUM  "0","1";
BA_DEF_ BO_  "GenMsgCycleTime" INT 0 50000;
BA_DEF_ BO_  "GenMsgSendType" ENUM  "cyclic","spontaneous","cyclicIfActive","spontaneousWithDelay","cyclicAndSpontaneous","cyclicAndSpontaneousWithDelay","spontaneousWithRepetition","cyclicIfActiveAndSpontaneousWD";
BA_DEF_  "DBName" STRING ;
BA_DEF_  "BusType" STRING ;
BA_DEF_ BO_  "VFrameFormat" ENUM  "StandardCAN","ExtendedCAN","reserved","reserved","reserved","reserved","reserved","reserved","reserved","reserved","reserved","reserved","reserved","reserved","StandardCAN_FD","ExtendedCAN_FD";
BA_DEF_DEF_  "CANFD_BRS" "1";
BA_DEF_DEF_  "GenMsgCycleTime" 100;
BA_DEF_DEF_  "GenMsgSendType" "cyclic";
BA_DEF_DEF_  "DBName" "";
BA_DEF_DEF_  "BusType" "";
BA_DEF_DEF_  "VFrameFormat" "StandardCAN";
BA_ "BusType" "CAN FD";
BA_ "DBName" "Gen5_Radar_LGU";
BA_ "GenMsgCycleTime" BO_ 16 20;
BA_ "VFrameFormat" BO_ 16 14;
BA_ "GenMsgCycleTime" BO_ 32 500;
BA_ "VFrameFormat" BO_ 32 14;
BA_ "GenMsgSendType" BO_ 1969 1;
BA_ "GenMsgCycleTime" BO_ 1969 0;
BA_ "VFrameFormat" BO_ 1969 14;
BA_ "GenMsgSendType" BO_ 1841 1;
BA_ "GenMsgCycleTime" BO_ 1841 0;
BA_ "VFrameFormat" BO_ 1841 14;
BA_ "GenMsgSendType" BO_ 2015 1;
BA_ "GenMsgCycleTime" BO_ 2015 0;
BA_ "VFrameFormat" BO_ 2015 14;
BA_ "VFrameFormat" BO_ 357 14;
BA_ "GenMsgSendType" BO_ 256 1;
BA_ "GenMsgCycleTime" BO_ 256 65;
BA_ "VFrameFormat" BO_ 256 14;
BA_ "GenMsgSendType" BO_ 356 1;
BA_ "GenMsgCycleTime" BO_ 356 65;
BA_ "VFrameFormat" BO_ 356 14;
BA_ "GenMsgSendType" BO_ 355 1;
BA_ "GenMsgCycleTime" BO_ 355 65;
BA_ "VFrameFormat" BO_ 355 14;
BA_ "GenMsgSendType" BO_ 354 1;
BA_ "GenMsgCycleTime" BO_ 354 65;
BA_ "VFrameFormat" BO_ 354 14;
BA_ "GenMsgSendType" BO_ 353 1;
BA_ "GenMsgCycleTime" BO_ 353 65;
BA_ "VFrameFormat" BO_ 353 14;
BA_ "GenMsgSendType" BO_ 352 1;
BA_ "GenMsgCycleTime" BO_ 352 65;
BA_ "VFrameFormat" BO_ 352 14;
BA_ "GenMsgSendType" BO_ 345 1;
BA_ "GenMsgCycleTime" BO_ 345 65;
BA_ "VFrameFormat" BO_ 345 14;
BA_ "GenMsgSendType" BO_ 344 1;
BA_ "GenMsgCycleTime" BO_ 344 65;
BA_ "VFrameFormat" BO_ 344 14;
BA_ "GenMsgSendType" BO_ 343 1;
BA_ "GenMsgCycleTime" BO_ 343 65;
BA_ "VFrameFormat" BO_ 343 14;
BA_ "GenMsgSendType" BO_ 342 1;
BA_ "GenMsgCycleTime" BO_ 342 65;
BA_ "VFrameFormat" BO_ 342 14;
BA_ "GenMsgSendType" BO_ 341 1;
BA_ "GenMsgCycleTime" BO_ 341 65;
BA_ "VFrameFormat" BO_ 341 14;
BA_ "GenMsgSendType" BO_ 340 1;
BA_ "GenMsgCycleTime" BO_ 340 65;
BA_ "VFrameFormat" BO_ 340 14;
BA_ "GenMsgSendType" BO_ 339 1;
BA_ "GenMsgCycleTime" BO_ 339 65;
BA_ "VFrameFormat" BO_ 339 14;
BA_ "GenMsgSendType" BO_ 338 1;
BA_ "GenMsgCycleTime" BO_ 338 65;
BA_ "VFrameFormat" BO_ 338 14;
BA_ "GenMsgSendType" BO_ 337 1;
BA_ "GenMsgCycleTime" BO_ 337 65;
BA_ "VFrameFormat" BO_ 337 14;
BA_ "GenMsgSendType" BO_ 336 1;
BA_ "GenMsgCycleTime" BO_ 336 65;
BA_ "VFrameFormat" BO_ 336 14;
BA_ "GenMsgSendType" BO_ 329 1;
BA_ "GenMsgCycleTime" BO_ 329 65;
BA_ "VFrameFormat" BO_ 329 14;
BA_ "GenMsgSendType" BO_ 328 1;
BA_ "GenMsgCycleTime" BO_ 328 65;
BA_ "VFrameFormat" BO_ 328 14;
BA_ "GenMsgSendType" BO_ 327 1;
BA_ "GenMsgCycleTime" BO_ 327 65;
BA_ "VFrameFormat" BO_ 327 14;
BA_ "GenMsgSendType" BO_ 326 1;
BA_ "GenMsgCycleTime" BO_ 326 65;
BA_ "VFrameFormat" BO_ 326 14;
BA_ "GenMsgSendType" BO_ 325 1;
BA_ "GenMsgCycleTime" BO_ 325 65;
BA_ "VFrameFormat" BO_ 325 14;
BA_ "GenMsgSendType" BO_ 324 1;
BA_ "GenMsgCycleTime" BO_ 324 65;
BA_ "VFrameFormat" BO_ 324 14;
BA_ "GenMsgSendType" BO_ 323 1;
BA_ "GenMsgCycleTime" BO_ 323 65;
BA_ "VFrameFormat" BO_ 323 14;
BA_ "GenMsgSendType" BO_ 322 1;
BA_ "GenMsgCycleTime" BO_ 322 65;
BA_ "VFrameFormat" BO_ 322 14;
BA_ "GenMsgSendType" BO_ 321 1;
BA_ "GenMsgCycleTime" BO_ 321 65;
BA_ "VFrameFormat" BO_ 321 14;
BA_ "GenMsgSendType" BO_ 320 1;
BA_ "GenMsgCycleTime" BO_ 320 65;
BA_ "VFrameFormat" BO_ 320 14;
BA_ "GenMsgSendType" BO_ 313 1;
BA_ "GenMsgCycleTime" BO_ 313 65;
BA_ "VFrameFormat" BO_ 313 14;
BA_ "GenMsgSendType" BO_ 312 1;
BA_ "GenMsgCycleTime" BO_ 312 65;
BA_ "VFrameFormat" BO_ 312 14;
BA_ "GenMsgSendType" BO_ 311 1;
BA_ "GenMsgCycleTime" BO_ 311 65;
BA_ "VFrameFormat" BO_ 311 14;
BA_ "GenMsgSendType" BO_ 310 1;
BA_ "GenMsgCycleTime" BO_ 310 65;
BA_ "VFrameFormat" BO_ 310 14;
BA_ "GenMsgSendType" BO_ 309 1;
BA_ "GenMsgCycleTime" BO_ 309 65;
BA_ "VFrameFormat" BO_ 309 14;
BA_ "GenMsgSendType" BO_ 308 1;
BA_ "GenMsgCycleTime" BO_ 308 65;
BA_ "VFrameFormat" BO_ 308 14;
BA_ "GenMsgSendType" BO_ 307 1;
BA_ "GenMsgCycleTime" BO_ 307 65;
BA_ "VFrameFormat" BO_ 307 14;
VAL_ 356 Loc_Validity_64_004 1 "Valid" 0 "Invalid" ;
VAL_ 356 Loc_Validity_64_003 1 "Valid" 0 "Invalid" ;
VAL_ 356 Loc_Validity_64_002 1 "Valid" 0 "Invalid" ;
VAL_ 356 Loc_Validity_64_001 1 "Valid" 0 "Invalid" ;
VAL_ 355 Loc_Validity_63_004 1 "Valid" 0 "Invalid" ;
VAL_ 355 Loc_Validity_63_003 1 "Valid" 0 "Invalid" ;
VAL_ 355 Loc_Validity_63_002 1 "Valid" 0 "Invalid" ;
VAL_ 355 Loc_Validity_63_001 1 "Valid" 0 "Invalid" ;
VAL_ 354 Loc_Validity_62_004 1 "Valid" 0 "Invalid" ;
VAL_ 354 Loc_Validity_62_003 1 "Valid" 0 "Invalid" ;
VAL_ 354 Loc_Validity_62_002 1 "Valid" 0 "Invalid" ;
VAL_ 354 Loc_Validity_62_001 1 "Valid" 0 "Invalid" ;
VAL_ 353 Loc_Validity_61_004 1 "Valid" 0 "Invalid" ;
VAL_ 353 Loc_Validity_61_003 1 "Valid" 0 "Invalid" ;
VAL_ 353 Loc_Validity_61_002 1 "Valid" 0 "Invalid" ;
VAL_ 353 Loc_Validity_61_001 1 "Valid" 0 "Invalid" ;
VAL_ 352 Loc_Validity_60_004 1 "Valid" 0 "Invalid" ;
VAL_ 352 Loc_Validity_60_003 1 "Valid" 0 "Invalid" ;
VAL_ 352 Loc_Validity_60_002 1 "Valid" 0 "Invalid" ;
VAL_ 352 Loc_Validity_60_001 1 "Valid" 0 "Invalid" ;
VAL_ 345 Loc_Validity_59_004 1 "Valid" 0 "Invalid" ;
VAL_ 345 Loc_Validity_59_003 1 "Valid" 0 "Invalid" ;
VAL_ 345 Loc_Validity_59_002 1 "Valid" 0 "Invalid" ;
VAL_ 345 Loc_Validity_59_001 1 "Valid" 0 "Invalid" ;
VAL_ 344 Loc_Validity_58_004 1 "Valid" 0 "Invalid" ;
VAL_ 344 Loc_Validity_58_003 1 "Valid" 0 "Invalid" ;
VAL_ 344 Loc_Validity_58_002 1 "Valid" 0 "Invalid" ;
VAL_ 344 Loc_Validity_58_001 1 "Valid" 0 "Invalid" ;
VAL_ 343 Loc_Validity_57_004 1 "Valid" 0 "Invalid" ;
VAL_ 343 Loc_Validity_57_003 1 "Valid" 0 "Invalid" ;
VAL_ 343 Loc_Validity_57_002 1 "Valid" 0 "Invalid" ;
VAL_ 343 Loc_Validity_57_001 1 "Valid" 0 "Invalid" ;
VAL_ 342 Loc_Validity_56_004 1 "Valid" 0 "Invalid" ;
VAL_ 342 Loc_Validity_56_003 1 "Valid" 0 "Invalid" ;
VAL_ 342 Loc_Validity_56_002 1 "Valid" 0 "Invalid" ;
VAL_ 342 Loc_Validity_56_001 1 "Valid" 0 "Invalid" ;
VAL_ 341 Loc_Validity_55_004 1 "Valid" 0 "Invalid" ;
VAL_ 341 Loc_Validity_55_003 1 "Valid" 0 "Invalid" ;
VAL_ 341 Loc_Validity_55_002 1 "Valid" 0 "Invalid" ;
VAL_ 341 Loc_Validity_55_001 1 "Valid" 0 "Invalid" ;
VAL_ 340 Loc_Validity_54_004 1 "Valid" 0 "Invalid" ;
VAL_ 340 Loc_Validity_54_003 1 "Valid" 0 "Invalid" ;
VAL_ 340 Loc_Validity_54_002 1 "Valid" 0 "Invalid" ;
VAL_ 340 Loc_Validity_54_001 1 "Valid" 0 "Invalid" ;
VAL_ 339 Loc_Validity_53_004 1 "Valid" 0 "Invalid" ;
VAL_ 339 Loc_Validity_53_003 1 "Valid" 0 "Invalid" ;
VAL_ 339 Loc_Validity_53_002 1 "Valid" 0 "Invalid" ;
VAL_ 339 Loc_Validity_53_001 1 "Valid" 0 "Invalid" ;
VAL_ 338 Loc_Validity_52_004 1 "Valid" 0 "Invalid" ;
VAL_ 338 Loc_Validity_52_003 1 "Valid" 0 "Invalid" ;
VAL_ 338 Loc_Validity_52_002 1 "Valid" 0 "Invalid" ;
VAL_ 338 Loc_Validity_52_001 1 "Valid" 0 "Invalid" ;
VAL_ 337 Loc_Validity_51_004 1 "Valid" 0 "Invalid" ;
VAL_ 337 Loc_Validity_51_003 1 "Valid" 0 "Invalid" ;
VAL_ 337 Loc_Validity_51_002 1 "Valid" 0 "Invalid" ;
VAL_ 337 Loc_Validity_51_001 1 "Valid" 0 "Invalid" ;
VAL_ 336 Loc_Validity_50_004 1 "Valid" 0 "Invalid" ;
VAL_ 336 Loc_Validity_50_003 1 "Valid" 0 "Invalid" ;
VAL_ 336 Loc_Validity_50_002 1 "Valid" 0 "Invalid" ;
VAL_ 336 Loc_Validity_50_001 1 "Valid" 0 "Invalid" ;
VAL_ 329 Loc_Validity_49_004 1 "Valid" 0 "Invalid" ;
VAL_ 329 Loc_Validity_49_003 1 "Valid" 0 "Invalid" ;
VAL_ 329 Loc_Validity_49_002 1 "Valid" 0 "Invalid" ;
VAL_ 329 Loc_Validity_49_001 1 "Valid" 0 "Invalid" ;
VAL_ 328 Loc_Validity_48_004 1 "Valid" 0 "Invalid" ;
VAL_ 328 Loc_Validity_48_003 1 "Valid" 0 "Invalid" ;
VAL_ 328 Loc_Validity_48_002 1 "Valid" 0 "Invalid" ;
VAL_ 328 Loc_Validity_48_001 1 "Valid" 0 "Invalid" ;
VAL_ 327 Loc_Validity_47_004 1 "Valid" 0 "Invalid" ;
VAL_ 327 Loc_Validity_47_003 1 "Valid" 0 "Invalid" ;
VAL_ 327 Loc_Validity_47_002 1 "Valid" 0 "Invalid" ;
VAL_ 327 Loc_Validity_47_001 1 "Valid" 0 "Invalid" ;
VAL_ 326 Loc_Validity_46_004 1 "Valid" 0 "Invalid" ;
VAL_ 326 Loc_Validity_46_003 1 "Valid" 0 "Invalid" ;
VAL_ 326 Loc_Validity_46_002 1 "Valid" 0 "Invalid" ;
VAL_ 326 Loc_Validity_46_001 1 "Valid" 0 "Invalid" ;
VAL_ 325 Loc_Validity_45_004 1 "Valid" 0 "Invalid" ;
VAL_ 325 Loc_Validity_45_003 1 "Valid" 0 "Invalid" ;
VAL_ 325 Loc_Validity_45_002 1 "Valid" 0 "Invalid" ;
VAL_ 325 Loc_Validity_45_001 1 "Valid" 0 "Invalid" ;
VAL_ 324 Loc_Validity_44_004 1 "Valid" 0 "Invalid" ;
VAL_ 324 Loc_Validity_44_003 1 "Valid" 0 "Invalid" ;
VAL_ 324 Loc_Validity_44_002 1 "Valid" 0 "Invalid" ;
VAL_ 324 Loc_Validity_44_001 1 "Valid" 0 "Invalid" ;
VAL_ 323 Loc_Validity_43_004 1 "Valid" 0 "Invalid" ;
VAL_ 323 Loc_Validity_43_003 1 "Valid" 0 "Invalid" ;
VAL_ 323 Loc_Validity_43_002 1 "Valid" 0 "Invalid" ;
VAL_ 323 Loc_Validity_43_001 1 "Valid" 0 "Invalid" ;
VAL_ 322 Loc_Validity_42_004 1 "Valid" 0 "Invalid" ;
VAL_ 322 Loc_Validity_42_003 1 "Valid" 0 "Invalid" ;
VAL_ 322 Loc_Validity_42_002 1 "Valid" 0 "Invalid" ;
VAL_ 322 Loc_Validity_42_001 1 "Valid" 0 "Invalid" ;
VAL_ 321 Loc_Validity_41_004 1 "Valid" 0 "Invalid" ;
VAL_ 321 Loc_Validity_41_003 1 "Valid" 0 "Invalid" ;
VAL_ 321 Loc_Validity_41_002 1 "Valid" 0 "Invalid" ;
VAL_ 321 Loc_Validity_41_001 1 "Valid" 0 "Invalid" ;
VAL_ 320 Loc_Validity_40_004 1 "Valid" 0 "Invalid" ;
VAL_ 320 Loc_Validity_40_003 1 "Valid" 0 "Invalid" ;
VAL_ 320 Loc_Validity_40_002 1 "Valid" 0 "Invalid" ;
VAL_ 320 Loc_Validity_40_001 1 "Valid" 0 "Invalid" ;
VAL_ 313 Loc_Validity_39_004 1 "Valid" 0 "Invalid" ;
VAL_ 313 Loc_Validity_39_003 1 "Valid" 0 "Invalid" ;
VAL_ 313 Loc_Validity_39_002 1 "Valid" 0 "Invalid" ;
VAL_ 313 Loc_Validity_39_001 1 "Valid" 0 "Invalid" ;
VAL_ 312 Loc_Validity_38_004 1 "Valid" 0 "Invalid" ;
VAL_ 312 Loc_Validity_38_003 1 "Valid" 0 "Invalid" ;
VAL_ 312 Loc_Validity_38_002 1 "Valid" 0 "Invalid" ;
VAL_ 312 Loc_Validity_38_001 1 "Valid" 0 "Invalid" ;
VAL_ 311 Loc_Validity_37_004 1 "Valid" 0 "Invalid" ;
VAL_ 311 Loc_Validity_37_003 1 "Valid" 0 "Invalid" ;
VAL_ 311 Loc_Validity_37_002 1 "Valid" 0 "Invalid" ;
VAL_ 311 Loc_Validity_37_001 1 "Valid" 0 "Invalid" ;
VAL_ 310 Loc_Validity_36_004 1 "Valid" 0 "Invalid" ;
VAL_ 310 Loc_Validity_36_003 1 "Valid" 0 "Invalid" ;
VAL_ 310 Loc_Validity_36_002 1 "Valid" 0 "Invalid" ;
VAL_ 310 Loc_Validity_36_001 1 "Valid" 0 "Invalid" ;
VAL_ 309 Loc_Validity_35_004 1 "Valid" 0 "Invalid" ;
VAL_ 309 Loc_Validity_35_003 1 "Valid" 0 "Invalid" ;
VAL_ 309 Loc_Validity_35_002 1 "Valid" 0 "Invalid" ;
VAL_ 309 Loc_Validity_35_001 1 "Valid" 0 "Invalid" ;
VAL_ 308 Loc_Validity_34_004 1 "Valid" 0 "Invalid" ;
VAL_ 308 Loc_Validity_34_003 1 "Valid" 0 "Invalid" ;
VAL_ 308 Loc_Validity_34_002 1 "Valid" 0 "Invalid" ;
VAL_ 308 Loc_Validity_34_001 1 "Valid" 0 "Invalid" ;
VAL_ 307 Loc_Validity_33_004 1 "Valid" 0 "Invalid" ;
VAL_ 307 Loc_Validity_33_003 1 "Valid" 0 "Invalid" ;
VAL_ 307 Loc_Validity_33_002 1 "Valid" 0 "Invalid" ;
VAL_ 307 Loc_Validity_33_001 1 "Valid" 0 "Invalid" ;
